VERSION ""

NS_ :

BS_:

BU_: Tester GW LAS

BO_ 1891 DIAG_Phy_Req_CAN: 8 Tester
 SG_ Phys_Diag_Rx_CAN : 7|8@0+ (1,0) [0|0] ""  LAS

BO_ 1899 DIAG_Response_CAN: 8 LAS
 SG_ Diag_Response_CAN : 7|8@0+ (1,0) [0|0] "" Vector__XXX

BO_ 2015 DIAG_Function_Req: 8 Tester
 SG_ Functional_Diag_Rx : 7|8@0+ (1,0) [0|0] ""  LAS

BO_ 1874 DIAG_Phy_Req: 64 Tester
 SG_ Phys_Diag_Rx : 7|64@0+ (1,0) [0|0] ""  LAS

BO_ 1882 DIAG_Response: 64 LAS
 SG_ Diag_Response : 7|64@0+ (1,0) [0|0] "" Vector__XXX

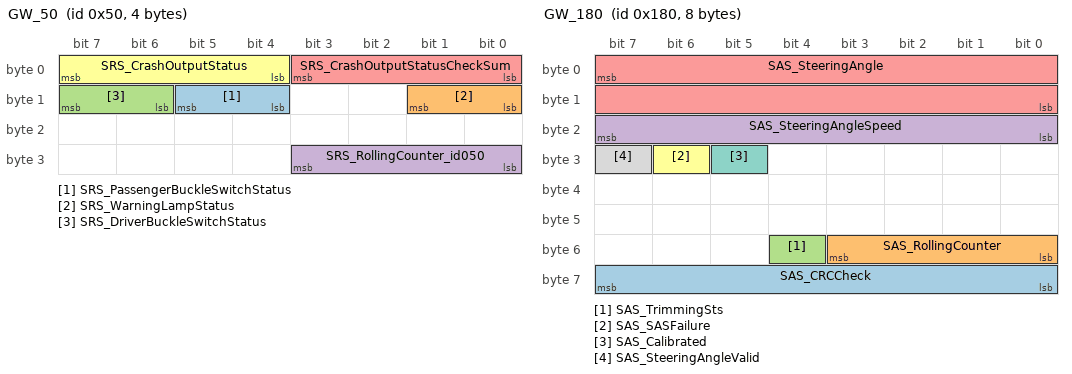
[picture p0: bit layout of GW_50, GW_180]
BO_ 80 GW_50: 4 GW
 SG_ SRS_PassengerBuckleSwitchStatus : 13|2@0+ (1,0) [0|3] ""  LAS
 SG_ SRS_WarningLampStatus : 9|2@0+ (1,0) [0|3] ""  LAS
 SG_ SRS_DriverBuckleSwitchStatus : 15|2@0+ (1,0) [0|3] ""  LAS
 SG_ SRS_RollingCounter_id050 : 27|4@0+ (1,0) [0|15] ""  LAS
 SG_ SRS_CrashOutputStatusCheckSum : 3|4@0+ (1,0) [0|15] ""  LAS
 SG_ SRS_CrashOutputStatus : 7|4@0+ (1,0) [0|15] ""  LAS

BO_ 384 GW_180: 8 GW
 SG_ SAS_CRCCheck : 63|8@0+ (1,0) [0|255] ""  LAS
 SG_ SAS_RollingCounter : 51|4@0+ (1,0) [0|15] ""  LAS
 SG_ SAS_TrimmingSts : 52|1@0+ (1,0) [0|1] ""  LAS
 SG_ SAS_SteeringAngleSpeed : 23|8@0+ (4,0) [0|1016] "deg/s"  LAS
 SG_ SAS_SteeringAngle : 7|16@0- (0.1,0) [-780|3276.7] "degree"  LAS
 SG_ SAS_SASFailure : 30|1@0+ (1,0) [0|1] ""  LAS
 SG_ SAS_Calibrated : 29|1@0+ (1,0) [0|1] ""  LAS
 SG_ SAS_SteeringAngleValid : 31|1@0+ (1,0) [0|1] ""  LAS

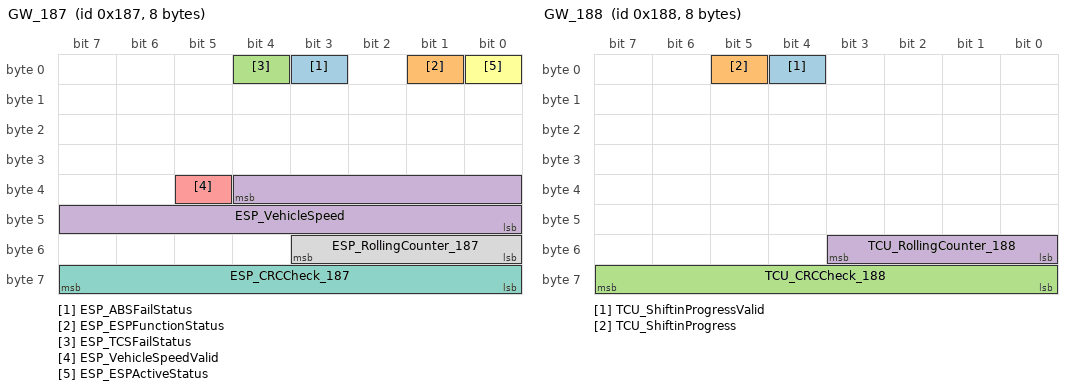
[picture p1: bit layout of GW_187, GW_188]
BO_ 391 GW_187: 8 GW
 SG_ ESP_ABSFailStatus : 3|1@0+ (1,0) [0|1] ""  LAS
 SG_ ESP_ESPFunctionStatus : 1|1@0+ (1,0) [0|1] ""  LAS
 SG_ ESP_TCSFailStatus : 4|1@0+ (1,0) [0|1] ""  LAS
 SG_ ESP_VehicleSpeed : 36|13@0+ (0.05625,0) [0|360] "km/h"  LAS
 SG_ ESP_VehicleSpeedValid : 37|1@0+ (1,0) [0|1] ""  LAS
 SG_ ESP_ESPActiveStatus : 0|1@0+ (1,0) [0|1] ""  LAS
 SG_ ESP_CRCCheck_187 : 63|8@0+ (1,0) [0|255] ""  LAS
 SG_ ESP_RollingCounter_187 : 51|4@0+ (1,0) [0|15] ""  LAS

BO_ 392 GW_188: 8 GW
 SG_ TCU_ShiftinProgressValid : 4|1@0+ (1,0) [0|1] ""  LAS
 SG_ TCU_ShiftinProgress : 5|1@0+ (1,0) [0|1] ""  LAS
 SG_ TCU_CRCCheck_188 : 63|8@0+ (1,0) [0|255] ""  LAS
 SG_ TCU_RollingCounter_188 : 51|4@0+ (1,0) [0|15] ""  LAS

BO_ 406 GW_196: 8 GW
 SG_ EMS_AccPedal : 47|8@0+ (0.392,0) [0|99.568] "%"  LAS
 SG_ EMS_EngineSpeed : 23|16@0+ (0.25,0) [0|16383.5] "Rpm"  LAS

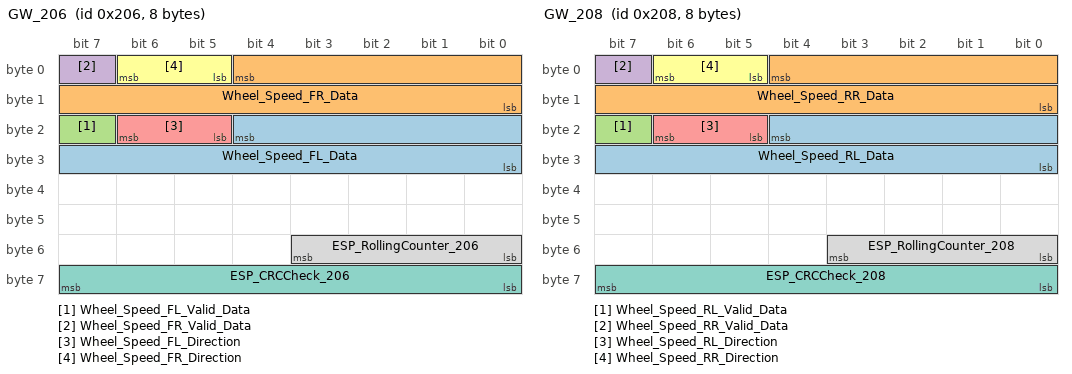
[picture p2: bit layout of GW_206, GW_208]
BO_ 518 GW_206: 8 GW
 SG_ Wheel_Speed_FL_Data : 20|13@0+ (0.05625,0) [0|360] "km/h"  LAS
 SG_ Wheel_Speed_FR_Data : 4|13@0+ (0.05625,0) [0|360] "km/h"  LAS
 SG_ Wheel_Speed_FL_Valid_Data : 23|1@0+ (1,0) [0|1] ""  LAS
 SG_ Wheel_Speed_FR_Valid_Data : 7|1@0+ (1,0) [0|1] ""  LAS
 SG_ Wheel_Speed_FL_Direction : 22|2@0+ (1,0) [0|3] ""  LAS
 SG_ Wheel_Speed_FR_Direction : 6|2@0+ (1,0) [0|3] ""  LAS
 SG_ ESP_CRCCheck_206 : 63|8@0+ (1,0) [0|255] ""  LAS
 SG_ ESP_RollingCounter_206 : 51|4@0+ (1,0) [0|15] ""  LAS

BO_ 520 GW_208: 8 GW
 SG_ Wheel_Speed_RL_Data : 20|13@0+ (0.05625,0) [0|360] "km/h"  LAS
 SG_ Wheel_Speed_RR_Data : 4|13@0+ (0.05625,0) [0|360] "km/h"  LAS
 SG_ Wheel_Speed_RL_Valid_Data : 23|1@0+ (1,0) [0|1] ""  LAS
 SG_ Wheel_Speed_RR_Valid_Data : 7|1@0+ (1,0) [0|1] ""  LAS
 SG_ Wheel_Speed_RL_Direction : 22|2@0+ (1,0) [0|3] ""  LAS
 SG_ Wheel_Speed_RR_Direction : 6|2@0+ (1,0) [0|3] ""  LAS
 SG_ ESP_CRCCheck_208 : 63|8@0+ (1,0) [0|255] ""  LAS
 SG_ ESP_RollingCounter_208 : 51|4@0+ (1,0) [0|15] ""  LAS

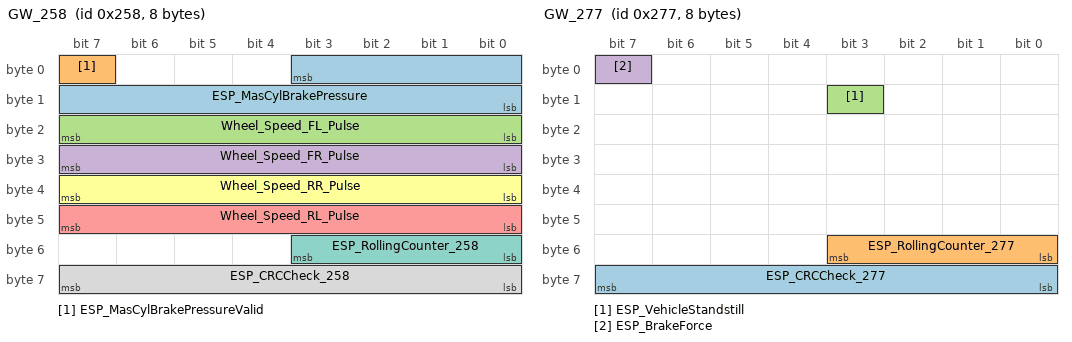
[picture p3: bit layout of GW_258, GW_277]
BO_ 600 GW_258: 8 GW
 SG_ ESP_MasCylBrakePressure : 3|12@0+ (0.1,0) [0|250] "Bar"  LAS
 SG_ ESP_MasCylBrakePressureValid : 7|1@0+ (1,0) [0|1] ""  LAS
 SG_ Wheel_Speed_FL_Pulse : 23|8@0+ (1,0) [0|254] ""  LAS
 SG_ Wheel_Speed_FR_Pulse : 31|8@0+ (1,0) [0|254] ""  LAS
 SG_ Wheel_Speed_RL_Pulse : 47|8@0+ (1,0) [0|254] ""  LAS
 SG_ Wheel_Speed_RR_Pulse : 39|8@0+ (1,0) [0|254] ""  LAS
 SG_ ESP_RollingCounter_258 : 51|4@0+ (1,0) [0|15] ""  LAS
 SG_ ESP_CRCCheck_258 : 63|8@0+ (1,0) [0|255] ""  LAS

BO_ 631 GW_277: 8 GW
 SG_ ESP_CRCCheck_277 : 63|8@0+ (1,0) [0|255] ""  LAS
 SG_ ESP_RollingCounter_277 : 51|4@0+ (1,0) [0|15] ""  LAS
 SG_ ESP_VehicleStandstill : 11|1@0+ (1,0) [0|1] ""  LAS
 SG_ ESP_BrakeForce : 7|1@0+ (1,0) [0|1] ""  LAS

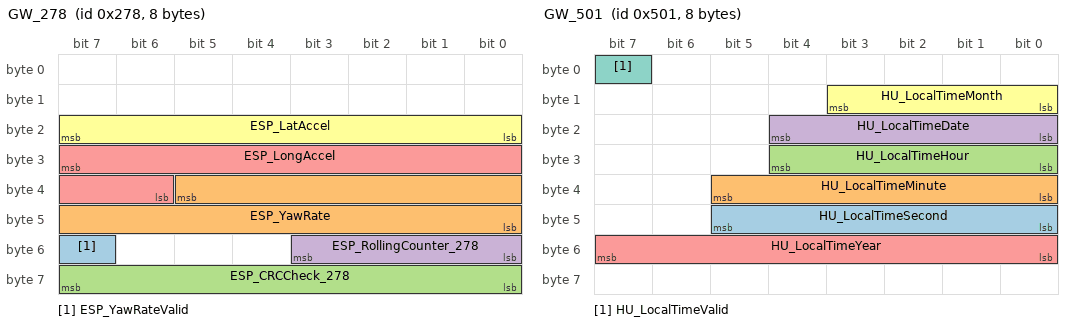
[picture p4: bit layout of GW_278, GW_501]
BO_ 632 GW_278: 8 GW
 SG_ ESP_YawRateValid : 55|1@0+ (1,0) [0|1] ""  LAS
 SG_ ESP_YawRate : 37|14@0+ (0.01,-81.91) [-81.91|81.91] "degree/s"  LAS
 SG_ ESP_CRCCheck_278 : 63|8@0+ (1,0) [0|255] ""  LAS
 SG_ ESP_RollingCounter_278 : 51|4@0+ (1,0) [0|15] ""  LAS
 SG_ ESP_LongAccel : 31|10@0+ (0.03125,-16) [-16|15.90625] "m/s2"  LAS
 SG_ ESP_LatAccel : 23|8@0+ (0.1,-12.7) [-12.7|12.7] "m/s2"  LAS

BO_ 832 GW_340: 8 GW
 SG_ AC_FrBlowType : 2|3@0+ (1,0) [0|7] ""  LAS

BO_ 870 GW_366: 8 GW
 SG_ AC_EnvironmentalTemp : 23|8@0+ (0.5,-40) [-40|87.5] "degreeC"  LAS
 SG_ AC_EnvironmentalTempVD : 8|1@0+ (1,0) [0|1] ""  LAS

BO_ 903 GW_387: 8 GW
 SG_ BCM_RainfallLevel : 19|4@0+ (1,0) [0|15] ""  LAS
 SG_ BCM_FrontWiperStatus : 25|2@0+ (1,0) [0|3] ""  LAS

BO_ 912 GW_390: 8 GW
 SG_ BCM_SOH_LifePercent : 15|8@0+ (1,0) [0|100] "%"  LAS
 SG_ BCM_PMSLevel : 5|3@0+ (1,0) [0|7] ""  LAS

BO_ 1280 GW_500: 8 GW
 SG_ HU_CurrentLocationLatitude : 35|28@0+ (1E-006,-134.217727) [-134.217727|90] "degree"  LAS
 SG_ HU_CurrentLocationLongitude : 4|29@0+ (1E-006,-268.435455) [-268.435455|180] "degree"  LAS

BO_ 1281 GW_501: 8 GW
 SG_ HU_LocalTimeSecond : 45|6@0+ (1,0) [0|59] "second"  LAS
 SG_ HU_LocalTimeMinute : 37|6@0+ (1,0) [0|59] "minute"  LAS
 SG_ HU_LocalTimeHour : 28|5@0+ (1,0) [0|23] "hour"  LAS
 SG_ HU_LocalTimeDate : 20|5@0+ (1,0) [1|31] "day"  LAS
 SG_ HU_LocalTimeYear : 55|8@0+ (1,2013) [2013|2268] "year"  LAS
 SG_ HU_LocalTimeMonth : 11|4@0+ (1,0) [1|12] "month"  LAS
 SG_ HU_LocalTimeValid : 7|1@0+ (1,0) [0|1] ""  LAS

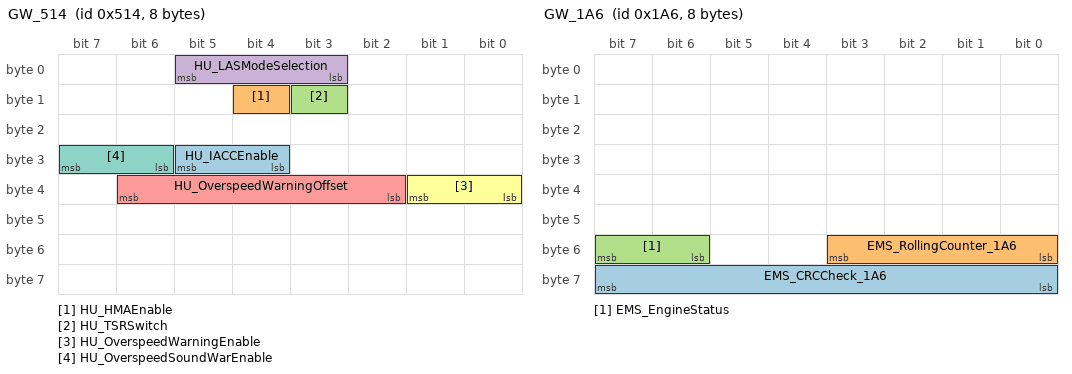
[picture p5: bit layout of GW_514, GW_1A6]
BO_ 1300 GW_514: 8 GW
 SG_ HU_IACCEnable : 29|2@0+ (1,0) [0|3] ""  LAS
 SG_ HU_HMAEnable : 12|1@0+ (1,0) [0|1] ""  LAS
 SG_ HU_TSRSwitch : 11|1@0+ (1,0) [0|1] ""  LAS
 SG_ HU_LASModeSelection : 5|3@0+ (1,0) [0|7] ""  LAS
 SG_ HU_OverspeedWarningOffset : 38|5@0+ (1,-10) [-10|10] ""  LAS
 SG_ HU_OverspeedWarningEnable : 33|2@0+ (1,0) [0|3] ""  LAS
 SG_ HU_OverspeedSoundWarEnable : 31|2@0+ (1,0) [0|3] ""  LAS

BO_ 1328 GW_530: 8 GW
 SG_ IP_TotalOdometer : 23|24@0+ (0.1,0) [0|999999] "Km"  LAS

BO_ 422 GW_1A6: 8 GW
 SG_ EMS_CRCCheck_1A6 : 63|8@0+ (1,0) [0|255] ""  LAS
 SG_ EMS_RollingCounter_1A6 : 51|4@0+ (1,0) [0|15] ""  LAS
 SG_ EMS_EngineStatus : 55|2@0+ (1,0) [0|3] ""  LAS

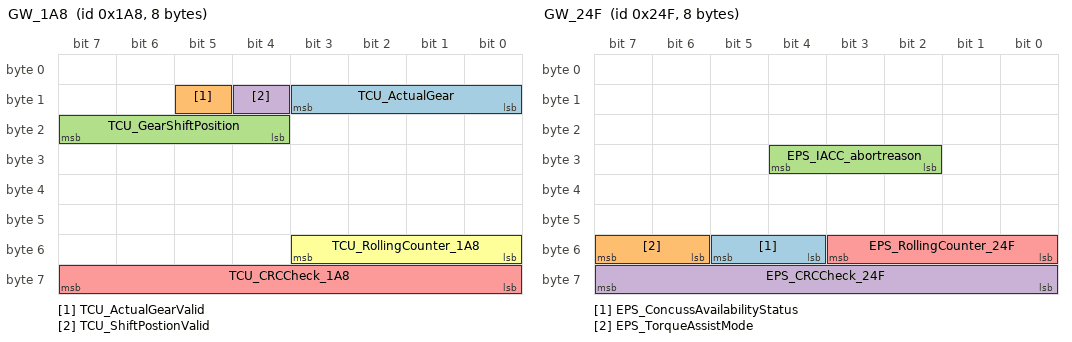
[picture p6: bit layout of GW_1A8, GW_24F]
BO_ 424 GW_1A8: 8 GW
 SG_ TCU_ActualGear : 11|4@0+ (1,0) [0|15] ""  LAS
 SG_ TCU_ActualGearValid : 13|1@0+ (1,0) [0|1] ""  LAS
 SG_ TCU_GearShiftPosition : 23|4@0+ (1,0) [0|15] ""  LAS
 SG_ TCU_ShiftPostionValid : 12|1@0+ (1,0) [0|1] ""  LAS
 SG_ TCU_CRCCheck_1A8 : 63|8@0+ (1,0) [0|255] ""  LAS
 SG_ TCU_RollingCounter_1A8 : 51|4@0+ (1,0) [0|15] ""  LAS

BO_ 591 GW_24F: 8 GW
 SG_ EPS_ConcussAvailabilityStatus : 53|2@0+ (1,0) [0|3] ""  LAS
 SG_ EPS_TorqueAssistMode : 55|2@0+ (1,0) [0|3] ""  LAS
 SG_ EPS_IACC_abortreason : 28|3@0+ (1,0) [0|7] ""  LAS
 SG_ EPS_CRCCheck_24F : 63|8@0+ (1,0) [0|255] ""  LAS
 SG_ EPS_RollingCounter_24F : 51|4@0+ (1,0) [0|15] ""  LAS

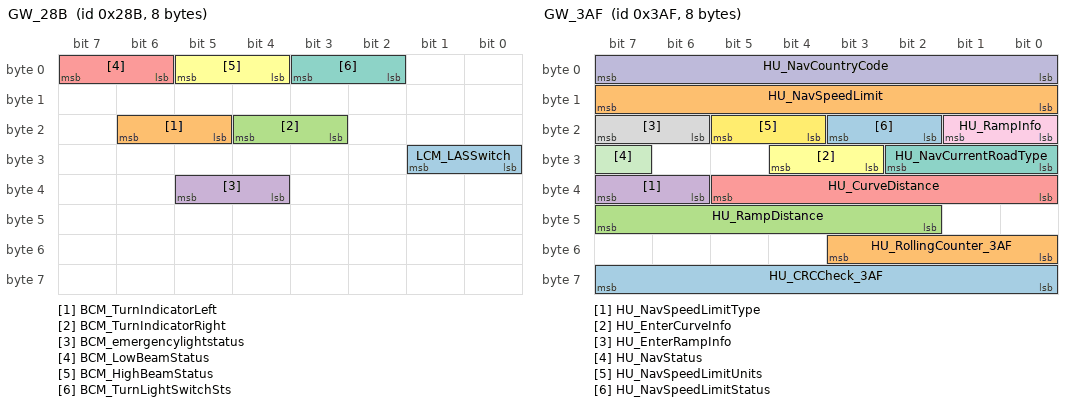
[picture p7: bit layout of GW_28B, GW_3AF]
BO_ 651 GW_28B: 8 GW
 SG_ LCM_LASSwitch : 25|2@0+ (1,0) [0|3] ""  LAS
 SG_ BCM_TurnIndicatorLeft : 22|2@0+ (1,0) [0|3] ""  LAS
 SG_ BCM_TurnIndicatorRight : 20|2@0+ (1,0) [0|3] ""  LAS
 SG_ BCM_emergencylightstatus : 37|2@0+ (1,0) [0|3] ""  LAS
 SG_ BCM_LowBeamStatus : 7|2@0+ (1,0) [0|3] ""  LAS
 SG_ BCM_HighBeamStatus : 5|2@0+ (1,0) [0|3] ""  LAS
 SG_ BCM_TurnLightSwitchSts : 3|2@0+ (1,0) [0|3] ""  LAS

BO_ 943 GW_3AF: 8 GW
 SG_ HU_CRCCheck_3AF : 63|8@0+ (1,0) [0|255] ""  LAS
 SG_ HU_RollingCounter_3AF : 51|4@0+ (1,0) [0|15] ""  LAS
 SG_ HU_RampDistance : 47|6@0+ (10,0) [0|630] "m"  LAS
 SG_ HU_NavSpeedLimitType : 39|2@0+ (1,0) [0|3] ""  LAS
 SG_ HU_CurveDistance : 37|6@0+ (10,0) [0|630] "m"  LAS
 SG_ HU_EnterCurveInfo : 28|2@0+ (1,0) [0|3] ""  LAS
 SG_ HU_NavCurrentRoadType : 26|3@0+ (1,0) [0|7] ""  LAS
 SG_ HU_EnterRampInfo : 23|2@0+ (1,0) [0|3] ""  LAS
 SG_ HU_RampInfo : 17|2@0+ (1,0) [0|3] ""  LAS
 SG_ HU_NavCountryCode : 7|8@0+ (1,0) [0|255] ""  LAS
 SG_ HU_NavStatus : 31|1@0+ (1,0) [0|1] ""  LAS
 SG_ HU_NavSpeedLimitUnits : 21|2@0+ (1,0) [0|3] ""  LAS
 SG_ HU_NavSpeedLimitStatus : 19|2@0+ (1,0) [0|3] ""  LAS
 SG_ HU_NavSpeedLimit : 15|8@0+ (1,0) [0|255] ""  LAS

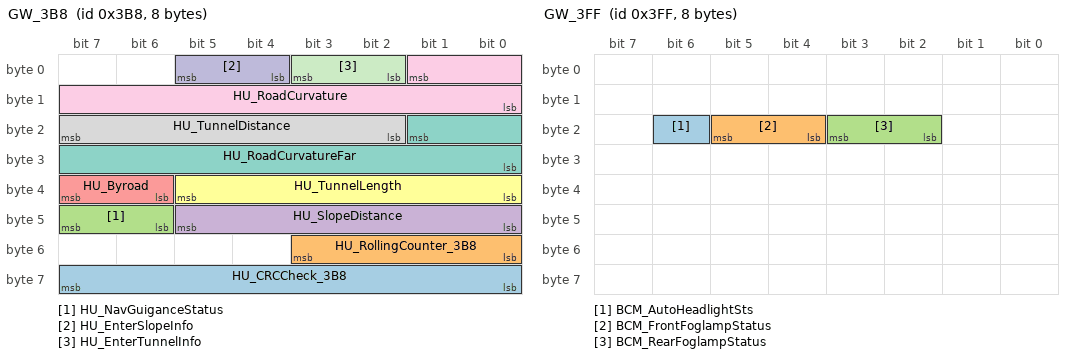
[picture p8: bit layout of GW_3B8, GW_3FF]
BO_ 952 GW_3B8: 8 GW
 SG_ HU_CRCCheck_3B8 : 63|8@0+ (1,0) [0|255] ""  LAS
 SG_ HU_RollingCounter_3B8 : 51|4@0+ (1,0) [0|15] ""  LAS
 SG_ HU_NavGuiganceStatus : 47|2@0+ (1,0) [0|3] ""  LAS
 SG_ HU_SlopeDistance : 45|6@0+ (10,0) [0|630] "m"  LAS
 SG_ HU_Byroad : 39|2@0+ (1,0) [0|3] ""  LAS
 SG_ HU_TunnelLength : 37|6@0+ (1,0) [0|63] "m"  LAS
 SG_ HU_RoadCurvatureFar : 17|10@0+ (1,0) [0|1023] ""  LAS
 SG_ HU_TunnelDistance : 23|6@0+ (10,0) [0|630] "m"  LAS
 SG_ HU_RoadCurvature : 1|10@0+ (1,0) [0|1023] ""  LAS
 SG_ HU_EnterSlopeInfo : 5|2@0+ (1,0) [0|3] ""  LAS
 SG_ HU_EnterTunnelInfo : 3|2@0+ (1,0) [0|3] ""  LAS

BO_ 1023 GW_3FF: 8 GW
 SG_ BCM_AutoHeadlightSts : 22|1@0+ (1,0) [0|1] ""  LAS
 SG_ BCM_FrontFoglampStatus : 21|2@0+ (1,0) [0|3] ""  LAS
 SG_ BCM_RearFoglampStatus : 19|2@0+ (1,0) [0|3] ""  LAS

BO_ 583 APA_247: 32 GW
 SG_ APA_APAOnOff : 6|1@0+ (1,0) [0|1] ""  LAS

BO_ 746 ADS_2EA: 16 GW
 SG_ ADS_LCDAR_BSD_LCAStatus : 23|2@0+ (1,0) [0|3] ""  LAS
 SG_ ADS_LCDAR_Left_BSD_LCAStatus : 3|2@0+ (1,0) [0|3] ""  LAS

BO_ 922 LAS_39A: 32 LAS
 SG_ LAS_TSRRightLaneStatus : 55|3@0+ (1,0) [0|7] "" Vector__XXX
 SG_ LAS_TSRLeftLaneStatus : 47|3@0+ (1,0) [0|7] "" Vector__XXX
 SG_ LAS_CRCCheck_3C0 : 191|8@0+ (1,0) [0|255] "" Vector__XXX
 SG_ LAS_RollingCounter_3C0 : 179|4@0+ (1,0) [0|15] "" Vector__XXX
 SG_ LAS_TSRRightLaneSpdLimit : 143|8@0+ (1,0) [0|255] "" Vector__XXX
 SG_ LAS_TSRLeftLaneSpdLimit : 135|8@0+ (1,0) [0|255] "" Vector__XXX
 SG_ LAS_CRCCheck_3D4 : 127|8@0+ (1,0) [0|255] "" Vector__XXX
 SG_ LAS_RollingCounter_3D4 : 115|4@0+ (1,0) [0|15] "" Vector__XXX
 SG_ LAS_TLAStopLine_HostLane : 111|8@0+ (1,0) [0|255] "" Vector__XXX
 SG_ LAS_TLADistance_HostLane : 103|8@0+ (1,0) [0|255] "" Vector__XXX
 SG_ LAS_TLACountDownTime_HostLane : 94|7@0+ (1,0) [0|127] "" Vector__XXX
 SG_ LAS_TSRMandatorySign : 70|4@0+ (1,0) [0|15] "" Vector__XXX
 SG_ LAS_TSRWarningSign : 83|4@0+ (1,0) [0|15] "" Vector__XXX
 SG_ LAS_TSRProhibitionSign : 66|5@0+ (1,0) [0|31] "" Vector__XXX
 SG_ LAS_CRCCheck_332 : 63|8@0+ (1,0) [0|255] "" Vector__XXX
 SG_ LAS_RollingCounter_332 : 51|4@0+ (1,0) [0|15] "" Vector__XXX
 SG_ LAS_OverspeedSoundWarningEnSt : 27|1@0+ (1,0) [0|1] "" Vector__XXX
 SG_ LAS_TSREnable : 30|1@0+ (1,0) [0|1] "" Vector__XXX
 SG_ LAS_HMAEnableStatus : 22|1@0+ (1,0) [0|1] "" Vector__XXX
 SG_ LAS_HMALightDistribution : 8|1@0+ (1,0) [0|1] "" Vector__XXX
 SG_ LAS_HMAStatus : 44|2@0+ (1,0) [0|3] "" Vector__XXX
 SG_ LAS_TSRHostSpdLimitUnits : 41|2@0+ (1,0) [0|3] "" Vector__XXX
 SG_ LAS_TSRHostSpdLimit : 39|8@0+ (1,0) [0|255] "" Vector__XXX
 SG_ LAS_TSRStatus : 26|3@0+ (1,0) [0|7] "" Vector__XXX
 SG_ LAS_FrontCameraCalibrationStatus : 20|2@0+ (1,0) [0|3] "" Vector__XXX
 SG_ LAS_FrontCameraFailureStatus : 17|2@0+ (1,0) [0|3] "" Vector__XXX
 SG_ LAS_OverspeedWarningOffset : 14|5@0+ (1,-10) [-10|10] "km/h" Vector__XXX
 SG_ LAS_OverspeedWarningEnableStatus : 15|1@0+ (1,0) [0|1] "" Vector__XXX
 SG_ LAS_OverspeedSoundWarning : 2|1@0+ (1,0) [0|1] "" Vector__XXX
 SG_ LAS_OverspeedVisualWarning : 5|1@0+ (1,0) [0|1] "" Vector__XXX
 SG_ LAS_CRCCheck_37D : 255|8@0+ (1,0) [0|255] "" Vector__XXX
 SG_ LAS_RollingCounter_37D : 243|4@0+ (1,0) [0|15] "" Vector__XXX
 SG_ LAS_TLAArrowDirection_RightLane : 236|3@0+ (1,0) [0|7] "" Vector__XXX
 SG_ LAS_TLAObjectType_RightLane : 239|3@0+ (1,0) [0|7] "" Vector__XXX
 SG_ LAS_TLAObjectStatus_RightLane : 247|2@0+ (1,0) [0|3] "" Vector__XXX
 SG_ LAS_TLAObjectColour_RightLane : 225|2@0+ (1,0) [0|3] "" Vector__XXX
 SG_ LAS_TLAObjectDetection_RightLane : 227|1@0+ (1,0) [0|1] "" Vector__XXX
 SG_ LAS_TLAArrowDirection_LeftLane : 216|3@0+ (1,0) [0|7] "" Vector__XXX
 SG_ LAS_TLAObjectType_LeftLane : 219|3@0+ (1,0) [0|7] "" Vector__XXX
 SG_ LAS_TLAObjectStatus_LeftLane : 245|2@0+ (1,0) [0|3] "" Vector__XXX
 SG_ LAS_TLAObjectColour_LeftLane : 221|2@0+ (1,0) [0|3] "" Vector__XXX
 SG_ LAS_TLAObjectDetection_LeftLane : 223|1@0+ (1,0) [0|1] "" Vector__XXX
 SG_ LAS_TLAArrowDirection_HostLane : 215|3@0+ (1,0) [0|7] "" Vector__XXX
 SG_ LAS_TLAObjectStatus_HostLane : 199|2@0+ (1,0) [0|3] "" Vector__XXX
 SG_ LAS_TLAObjectType_HostLane : 212|3@0+ (1,0) [0|7] "" Vector__XXX
 SG_ LAS_TLAObjectColour_HostLane : 204|2@0+ (1,0) [0|3] "" Vector__XXX
 SG_ LAS_TLAObjectDetection_HostLane : 200|1@0+ (1,0) [0|1] "" Vector__XXX
 SG_ LAS_TLAWarninglevel : 197|2@0+ (1,0) [0|3] "" Vector__XXX
 SG_ LAS_TLAStatus : 193|2@0+ (1,0) [0|3] "" Vector__XXX
 SG_ LAS_TLAEnable : 194|1@0+ (1,0) [0|1] "" Vector__XXX

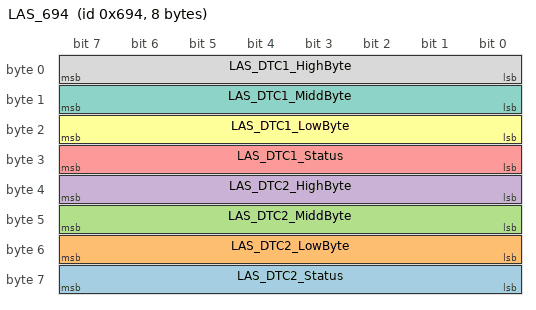
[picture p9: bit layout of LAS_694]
BO_ 1684 LAS_694: 8 LAS
 SG_ LAS_DTC2_Status : 63|8@0+ (1,0) [0|255] "" Vector__XXX
 SG_ LAS_DTC2_LowByte : 55|8@0+ (1,0) [0|255] "" Vector__XXX
 SG_ LAS_DTC2_MiddByte : 47|8@0+ (1,0) [0|255] "" Vector__XXX
 SG_ LAS_DTC2_HighByte : 39|8@0+ (1,0) [0|255] "" Vector__XXX
 SG_ LAS_DTC1_Status : 31|8@0+ (1,0) [0|255] "" Vector__XXX
 SG_ LAS_DTC1_LowByte : 23|8@0+ (1,0) [0|255] "" Vector__XXX
 SG_ LAS_DTC1_MiddByte : 15|8@0+ (1,0) [0|255] "" Vector__XXX
 SG_ LAS_DTC1_HighByte : 7|8@0+ (1,0) [0|255] "" Vector__XXX

BO_ 999 GW_3E7: 8 GW
 SG_ BCM_Status_Temp : 51|2@0+ (1,0) [0|3] ""  LAS
 SG_ BCM_T_BATT : 39|8@0+ (1,-40) [-40|215] ""  LAS

BO_ 1000 GW_3E8: 8 GW
 SG_ BCM_SOF_Q_STATE : 51|2@0+ (1,0) [0|3] ""  LAS
 SG_ BCM_SOF_Q : 15|8@0+ (0.5,0) [0|127.5] "Ah"  LAS

BO_TX_BU_ 1882 : Tester,LAS;

CM_ BO_ 2015 " ";
CM_ BO_ 1874 " ";
CM_ BO_ 1882 " ";
CM_ BO_ 80 "
20ms 10 ";
CM_ SG_ 80 SRS_PassengerBuckleSwitchStatus "For PDM is configured projects:
(if PDM is configured, logical detection with PDM is required)
0x0: [Buckled] or [Unbuckled and passenger not occupied]
0x1: [Unbuckle and passenger occupied]
0x2: Not Used
0x3: Not Used
 ";
CM_ BO_ 384 "PCAN_SAS»
EPS EPSCAN_EPS ";
CM_ BO_ 391 " ";
CM_ SG_ 391 ESP_VehicleSpeed "TCUDCT ";
CM_ SG_ 391 ESP_VehicleSpeedValid "TCUDCT ";
CM_ SG_ 391 ESP_ESPActiveStatus "TCUDCT ";
CM_ SG_ 391 ESP_CRCCheck_187 "AT/DCT ";
CM_ SG_ 391 ESP_RollingCounter_187 "AT/DCT ";
CM_ BO_ 392 " ";
CM_ SG_ 392 TCU_ShiftinProgressValid "AT/DCT ";
CM_ SG_ 392 TCU_ShiftinProgress "AT/DCT ";
CM_ SG_ 392 TCU_CRCCheck_188 " ";
CM_ SG_ 392 TCU_RollingCounter_188 "AT/DCT
rollingcounter ";
CM_ BO_ 406 " ";
CM_ BO_ 518 " ";
CM_ SG_ 518 ESP_CRCCheck_206 " ";
CM_ SG_ 518 ESP_RollingCounter_206 "rollingcounter ";
CM_ BO_ 520 " ";
CM_ SG_ 520 ESP_CRCCheck_208 " ";
CM_ SG_ 520 ESP_RollingCounter_208 "rollingcounter ";
CM_ BO_ 600 " ";
CM_ SG_ 600 ESP_MasCylBrakePressure "indicatedthepressureofbrakemastercylinder,butnotthepressureofbrake ";
CM_ SG_ 600 Wheel_Speed_FL_Pulse "All4wheelpulsesignalsaresentbyABSwithoutfiltering.Theriseedgeandfalledgearebothcountedinit,thewheelpulsemustbesequentialintheway0,1,2,254,0,4";
CM_ SG_ 600 Wheel_Speed_FR_Pulse "All4wheelpulsesignalsaresentbyABSwithoutfiltering.Theriseedgeandfalledgearebothcountedinit,thewheelpulsemustbesequentialintheway0,1,2,254,0,3 ";
CM_ SG_ 600 Wheel_Speed_RL_Pulse "All4wheelpulsesignalsaresentbyABSwithoutfiltering.Theriseedgeandfalledgearebothcountedinit,thewheelpulsemustbesequentialintheway0,1,2,254,0,2 ";
CM_ SG_ 600 Wheel_Speed_RR_Pulse "All4wheelpulsesignalsaresentbyABSwithoutfiltering.Theriseedgeandfalledgearebothcountedinit,thewheelpulsemustbesequentialintheway0,1,2,254,0,1 ";
CM_ SG_ 600 ESP_CRCCheck_258 " ";
CM_ BO_ 631 " ";
CM_ SG_ 631 ESP_CRCCheck_277 " ";
CM_ SG_ 631 ESP_RollingCounter_277 "rollingcounter ";
CM_ BO_ 632 " ";
CM_ SG_ 632 ESP_YawRate " ";
CM_ SG_ 632 ESP_CRCCheck_278 " ";
CM_ SG_ 632 ESP_RollingCounter_278 "rollingcounter ";
CM_ SG_ 632 ESP_LongAccel " ";
CM_ SG_ 632 ESP_LatAccel " ";
CM_ BO_ 832 " ";
CM_ BO_ 870 " ";
CM_ BO_ 903 " ";
CM_ BO_ 912 " ";
CM_ SG_ 912 BCM_PMSLevel "DBC ";
CM_ BO_ 1280 " ";
CM_ BO_ 1281 " ";
CM_ BO_ 1300 " ";
CM_ SG_ 1300 HU_IACCEnable "513()514()514() ";
CM_ SG_ 1300 HU_HMAEnable "513()514()514() ";
CM_ SG_ 1300 HU_TSRSwitch "513()514()514() ";
CM_ SG_ 1300 HU_LASModeSelection "513()514()514() ";
CM_ SG_ 1300 HU_OverspeedWarningOffset "513()514()514() ";
CM_ SG_ 1300 HU_OverspeedWarningEnable "513()514()514() ";
CM_ SG_ 1300 HU_OverspeedSoundWarEnable "513()514()514() ";
CM_ BO_ 1328 " ";
CM_ SG_ 1328 IP_TotalOdometer "GW ";
CM_ BO_ 422 " ";
CM_ SG_ 422 EMS_CRCCheck_1A6 " ";
CM_ BO_ 424 " ";
CM_ SG_ 424 TCU_ActualGear "AT/DCT ";
CM_ SG_ 424 TCU_ActualGearValid "AT/DCT ";
CM_ SG_ 424 TCU_GearShiftPosition "AT/DCT ";
CM_ SG_ 424 TCU_ShiftPostionValid "AT/DCT ";
CM_ SG_ 424 TCU_CRCCheck_1A8 " ";
CM_ SG_ 424 TCU_RollingCounter_1A8 "AT/DCT
rollingcounter ";
CM_ BO_ 591 "L2EPSCAN L2PCAN ";
CM_ BO_ 651 " ";
CM_ BO_ 943 " ";
CM_ BO_ 952 " ";
CM_ BO_ 1023 " ";
CM_ BO_ 583 " ";
CM_ BO_ 746 " ";
CM_ SG_ 746 ADS_LCDAR_Left_BSD_LCAStatus " ";
CM_ BO_ 922 " ";
CM_ SG_ 922 LAS_TSRRightLaneStatus "GW ";
CM_ SG_ 922 LAS_TSRLeftLaneStatus "GW ";
CM_ SG_ 922 LAS_CRCCheck_3C0 "
 ";
CM_ SG_ 922 LAS_RollingCounter_3C0 "rolling counter ";
CM_ SG_ 922 LAS_TSRRightLaneSpdLimit "GW
0x0=no speed limit detected;
0x1=SL5;
0x2=SL10;
0x32=SL160;
0x33~0x253= Reserved;
0x254=Unknown;
0x255=SLEND ";
CM_ SG_ 922 LAS_TSRLeftLaneSpdLimit "GW
0x0=no speed limit detected;
0x1=SL5;
0x2=SL10;
0x32=SL160;
0x33~0x253= Reserved;
0x254=Unknown;
0x255=SLEND ";
CM_ SG_ 922 LAS_CRCCheck_3D4 "
 ";
CM_ SG_ 922 LAS_RollingCounter_3D4 "rolling counter ";
CM_ SG_ 922 LAS_TLAStopLine_HostLane " ";
CM_ SG_ 922 LAS_TLADistance_HostLane " ";
CM_ SG_ 922 LAS_TLACountDownTime_HostLane " ";
CM_ SG_ 922 LAS_TSRMandatorySign " ";
CM_ SG_ 922 LAS_TSRWarningSign " ";
CM_ SG_ 922 LAS_TSRProhibitionSign " ";
CM_ SG_ 922 LAS_CRCCheck_332 "
 ";
CM_ SG_ 922 LAS_RollingCounter_332 "rolling counter ";
CM_ SG_ 922 LAS_HMALightDistribution "GW ";
CM_ SG_ 922 LAS_HMAStatus "GW ";
CM_ SG_ 922 LAS_TSRHostSpdLimitUnits "GW ";
CM_ SG_ 922 LAS_TSRStatus "GW ";
CM_ SG_ 922 LAS_FrontCameraCalibrationStatus "LASLAS APAAVM ";
CM_ SG_ 922 LAS_FrontCameraFailureStatus "LASLAS APAAVM ";
CM_ SG_ 922 LAS_CRCCheck_37D " ";
CM_ SG_ 922 LAS_RollingCounter_37D "rolling counter ";
CM_ SG_ 922 LAS_TLAArrowDirection_RightLane " ";
CM_ SG_ 922 LAS_TLAObjectType_RightLane " ";
CM_ SG_ 922 LAS_TLAObjectStatus_RightLane " ";
CM_ SG_ 922 LAS_TLAObjectColour_RightLane " ";
CM_ SG_ 922 LAS_TLAObjectDetection_RightLane " ";
CM_ SG_ 922 LAS_TLAArrowDirection_LeftLane " ";
CM_ SG_ 922 LAS_TLAObjectType_LeftLane " ";
CM_ SG_ 922 LAS_TLAObjectStatus_LeftLane " ";
CM_ SG_ 922 LAS_TLAObjectColour_LeftLane " ";
CM_ SG_ 922 LAS_TLAObjectDetection_LeftLane " ";
CM_ SG_ 922 LAS_TLAArrowDirection_HostLane " ";
CM_ SG_ 922 LAS_TLAObjectStatus_HostLane " ";
CM_ SG_ 922 LAS_TLAObjectType_HostLane " ";
CM_ SG_ 922 LAS_TLAObjectColour_HostLane " ";
CM_ SG_ 922 LAS_TLAObjectDetection_HostLane " ";
CM_ SG_ 922 LAS_TLAWarninglevel " ";
CM_ SG_ 922 LAS_TLAStatus " ";
CM_ SG_ 922 LAS_TLAEnable " ";
CM_ BO_ 1684 " ";
CM_ SG_ 1684 LAS_DTC2_Status "DTC ";
CM_ SG_ 1684 LAS_DTC2_LowByte "DTC ";
CM_ SG_ 1684 LAS_DTC2_MiddByte "DTC ";
CM_ SG_ 1684 LAS_DTC2_HighByte "DTC ";
CM_ SG_ 1684 LAS_DTC1_Status "DTC ";
CM_ SG_ 1684 LAS_DTC1_LowByte "DTC ";
CM_ SG_ 1684 LAS_DTC1_MiddByte "DTC ";
CM_ SG_ 1684 LAS_DTC1_HighByte "DTC ";
CM_ BO_ 999 " ";
CM_ SG_ 999 BCM_Status_Temp "GW ";
CM_ SG_ 999 BCM_T_BATT "GW ";
CM_ BO_ 1000 " ";
CM_ SG_ 1000 BCM_SOF_Q_STATE "GW ";
CM_ SG_ 1000 BCM_SOF_Q "GW ";
BA_DEF_  "BusType" STRING ;
BA_DEF_ SG_  "GenSigSendType" ENUM  "Cyclic","OnWrite","OnWriteWithRepetition","OnChange","OnChangeWithRepetition","IfActive","IfActiveWithRepetition","NoSigSendType","NotUsed","NotUsed","NotUsed","NotUsed","NotUsed";
BA_DEF_ SG_  "GenSigCycleTime" INT 0 0;
BA_DEF_ SG_  "GenSigInvalidValue" STRING ;
BA_DEF_ SG_  "GenSigStartValue" INT 0 0;
BA_DEF_ BO_  "VFrameFormat" ENUM  "StandardCAN","ExtendedCAN","reserved","reserved","reserved","reserved","reserved","reserved","reserved","reserved","reserved","reserved","reserved","reserved","StandardCAN_FD","ExtendedCAN_FD";
BA_DEF_ BO_  "CANFD_BRS" ENUM  "0","1";
BA_DEF_ BO_  "GenMsgCycleTime" INT 0 65535;
BA_DEF_ BO_  "GenMsgILSupport" ENUM  "No","Yes";
BA_DEF_ BO_  "GenMsgSendType" ENUM  "Cyclic","Event","NotUsed","NotUsed","NotUsed","Cyclic","NotUsed","IfActive","NoMsgSendType","NotUsed";
BA_DEF_ BU_  "ILUsed" ENUM  "No","Yes";
BA_DEF_ BU_  "NodeLayerModules" STRING ;
BA_DEF_DEF_  "BusType" "";
BA_DEF_DEF_  "GenSigSendType" "Cyclic";
BA_DEF_DEF_  "GenSigCycleTime" 0;
BA_DEF_DEF_  "GenSigInvalidValue" "/";
BA_DEF_DEF_  "GenSigStartValue" 0;
BA_DEF_DEF_  "VFrameFormat" "StandardCAN";
BA_DEF_DEF_  "CANFD_BRS" "1";
BA_DEF_DEF_  "GenMsgCycleTime" 0;
BA_DEF_DEF_  "GenMsgILSupport" "Yes";
BA_DEF_DEF_  "GenMsgSendType" "NoMsgSendType";
BA_DEF_DEF_  "ILUsed" "Yes";
BA_DEF_DEF_  "NodeLayerModules" "OSEKNM01.dll,CANoeILNLVector.dll";
BA_ "BusType" "CAN";
BA_ "VFrameFormat" BO_ 1874 14;
BA_ "VFrameFormat" BO_ 1882 14;
BA_ "GenMsgSendType" BO_ 80 0;
BA_ "GenMsgCycleTime" BO_ 80 500;
BA_ "VFrameFormat" BO_ 80 14;
BA_ "GenMsgSendType" BO_ 384 0;
BA_ "GenMsgCycleTime" BO_ 384 10;
BA_ "VFrameFormat" BO_ 384 14;
BA_ "GenMsgSendType" BO_ 391 0;
BA_ "GenMsgCycleTime" BO_ 391 10;
BA_ "VFrameFormat" BO_ 391 14;
BA_ "GenMsgSendType" BO_ 392 0;
BA_ "GenMsgCycleTime" BO_ 392 10;
BA_ "VFrameFormat" BO_ 392 14;
BA_ "GenMsgSendType" BO_ 406 0;
BA_ "GenMsgCycleTime" BO_ 406 10;
BA_ "VFrameFormat" BO_ 406 14;
BA_ "GenMsgSendType" BO_ 518 0;
BA_ "GenMsgCycleTime" BO_ 518 20;
BA_ "VFrameFormat" BO_ 518 14;
BA_ "GenMsgSendType" BO_ 520 0;
BA_ "GenMsgCycleTime" BO_ 520 20;
BA_ "VFrameFormat" BO_ 520 14;
BA_ "GenMsgSendType" BO_ 600 0;
BA_ "GenMsgCycleTime" BO_ 600 20;
BA_ "VFrameFormat" BO_ 600 14;
BA_ "GenMsgSendType" BO_ 631 0;
BA_ "GenMsgCycleTime" BO_ 631 20;
BA_ "VFrameFormat" BO_ 631 14;
BA_ "GenMsgSendType" BO_ 632 0;
BA_ "GenMsgCycleTime" BO_ 632 20;
BA_ "VFrameFormat" BO_ 632 14;
BA_ "GenMsgSendType" BO_ 832 0;
BA_ "GenMsgCycleTime" BO_ 832 100;
BA_ "VFrameFormat" BO_ 832 14;
BA_ "GenMsgSendType" BO_ 870 0;
BA_ "GenMsgCycleTime" BO_ 870 100;
BA_ "VFrameFormat" BO_ 870 14;
BA_ "GenMsgSendType" BO_ 903 0;
BA_ "GenMsgCycleTime" BO_ 903 100;
BA_ "VFrameFormat" BO_ 903 14;
BA_ "GenMsgSendType" BO_ 912 0;
BA_ "GenMsgCycleTime" BO_ 912 500;
BA_ "VFrameFormat" BO_ 912 14;
BA_ "GenMsgSendType" BO_ 1280 0;
BA_ "GenMsgCycleTime" BO_ 1280 1000;
BA_ "VFrameFormat" BO_ 1280 14;
BA_ "GenMsgSendType" BO_ 1281 0;
BA_ "GenMsgCycleTime" BO_ 1281 1000;
BA_ "VFrameFormat" BO_ 1281 14;
BA_ "GenMsgSendType" BO_ 1300 1;
BA_ "VFrameFormat" BO_ 1300 14;
BA_ "GenMsgSendType" BO_ 1328 0;
BA_ "GenMsgCycleTime" BO_ 1328 500;
BA_ "VFrameFormat" BO_ 1328 14;
BA_ "GenMsgSendType" BO_ 422 0;
BA_ "GenMsgCycleTime" BO_ 422 10;
BA_ "VFrameFormat" BO_ 422 14;
BA_ "GenMsgSendType" BO_ 424 0;
BA_ "GenMsgCycleTime" BO_ 424 10;
BA_ "VFrameFormat" BO_ 424 14;
BA_ "GenMsgSendType" BO_ 591 0;
BA_ "GenMsgCycleTime" BO_ 591 20;
BA_ "VFrameFormat" BO_ 591 14;
BA_ "GenMsgSendType" BO_ 651 0;
BA_ "GenMsgCycleTime" BO_ 651 40;
BA_ "VFrameFormat" BO_ 651 14;
BA_ "GenMsgSendType" BO_ 943 0;
BA_ "GenMsgCycleTime" BO_ 943 100;
BA_ "VFrameFormat" BO_ 943 14;
BA_ "GenMsgSendType" BO_ 952 0;
BA_ "GenMsgCycleTime" BO_ 952 100;
BA_ "VFrameFormat" BO_ 952 14;
BA_ "GenMsgSendType" BO_ 1023 0;
BA_ "GenMsgCycleTime" BO_ 1023 100;
BA_ "VFrameFormat" BO_ 1023 14;
BA_ "GenMsgSendType" BO_ 583 0;
BA_ "GenMsgCycleTime" BO_ 583 20;
BA_ "VFrameFormat" BO_ 583 14;
BA_ "GenMsgSendType" BO_ 746 0;
BA_ "GenMsgCycleTime" BO_ 746 50;
BA_ "VFrameFormat" BO_ 746 14;
BA_ "GenMsgSendType" BO_ 922 0;
BA_ "GenMsgCycleTime" BO_ 922 100;
BA_ "VFrameFormat" BO_ 922 14;
BA_ "GenMsgSendType" BO_ 1684 0;
BA_ "GenMsgCycleTime" BO_ 1684 500;
BA_ "VFrameFormat" BO_ 1684 14;
BA_ "GenMsgSendType" BO_ 999 0;
BA_ "GenMsgCycleTime" BO_ 999 100;
BA_ "VFrameFormat" BO_ 999 14;
BA_ "GenMsgSendType" BO_ 1000 0;
BA_ "GenMsgCycleTime" BO_ 1000 100;
BA_ "VFrameFormat" BO_ 1000 14;
BA_ "GenSigCycleTime" SG_ 80 SRS_PassengerBuckleSwitchStatus 500;
BA_ "GenSigCycleTime" SG_ 80 SRS_WarningLampStatus 500;
BA_ "GenSigCycleTime" SG_ 80 SRS_DriverBuckleSwitchStatus 500;
BA_ "GenSigCycleTime" SG_ 80 SRS_RollingCounter_id050 500;
BA_ "GenSigCycleTime" SG_ 80 SRS_CrashOutputStatusCheckSum 500;
BA_ "GenSigCycleTime" SG_ 80 SRS_CrashOutputStatus 500;
BA_ "GenSigCycleTime" SG_ 384 SAS_CRCCheck 10;
BA_ "GenSigCycleTime" SG_ 384 SAS_RollingCounter 10;
BA_ "GenSigCycleTime" SG_ 384 SAS_TrimmingSts 10;
BA_ "GenSigInvalidValue" SG_ 384 SAS_SteeringAngleSpeed "255";
BA_ "GenSigCycleTime" SG_ 384 SAS_SteeringAngleSpeed 10;
BA_ "GenSigStartValue" SG_ 384 SAS_SteeringAngle 32767;
BA_ "GenSigInvalidValue" SG_ 384 SAS_SteeringAngle "32767";
BA_ "GenSigCycleTime" SG_ 384 SAS_SteeringAngle 10;
BA_ "GenSigInvalidValue" SG_ 384 SAS_SASFailure "1";
BA_ "GenSigCycleTime" SG_ 384 SAS_SASFailure 10;
BA_ "GenSigInvalidValue" SG_ 384 SAS_Calibrated "LastValue";
BA_ "GenSigCycleTime" SG_ 384 SAS_Calibrated 10;
BA_ "GenSigInvalidValue" SG_ 384 SAS_SteeringAngleValid "1";
BA_ "GenSigCycleTime" SG_ 384 SAS_SteeringAngleValid 10;
BA_ "GenSigCycleTime" SG_ 391 ESP_ABSFailStatus 10;
BA_ "GenSigStartValue" SG_ 391 ESP_ESPFunctionStatus 1;
BA_ "GenSigCycleTime" SG_ 391 ESP_ESPFunctionStatus 10;
BA_ "GenSigCycleTime" SG_ 391 ESP_TCSFailStatus 10;
BA_ "GenSigInvalidValue" SG_ 391 ESP_VehicleSpeed "8191";
BA_ "GenSigCycleTime" SG_ 391 ESP_VehicleSpeed 10;
BA_ "GenSigInvalidValue" SG_ 391 ESP_VehicleSpeedValid "1";
BA_ "GenSigCycleTime" SG_ 391 ESP_VehicleSpeedValid 10;
BA_ "GenSigCycleTime" SG_ 391 ESP_ESPActiveStatus 10;
BA_ "GenSigCycleTime" SG_ 391 ESP_CRCCheck_187 10;
BA_ "GenSigCycleTime" SG_ 391 ESP_RollingCounter_187 10;
BA_ "GenSigInvalidValue" SG_ 392 TCU_ShiftinProgressValid "1";
BA_ "GenSigCycleTime" SG_ 392 TCU_ShiftinProgressValid 10;
BA_ "GenSigCycleTime" SG_ 392 TCU_ShiftinProgress 10;
BA_ "GenSigCycleTime" SG_ 392 TCU_CRCCheck_188 10;
BA_ "GenSigCycleTime" SG_ 392 TCU_RollingCounter_188 10;
BA_ "GenSigInvalidValue" SG_ 406 EMS_AccPedal "255";
BA_ "GenSigCycleTime" SG_ 406 EMS_AccPedal 10;
BA_ "GenSigInvalidValue" SG_ 406 EMS_EngineSpeed "65535";
BA_ "GenSigCycleTime" SG_ 406 EMS_EngineSpeed 10;
BA_ "GenSigInvalidValue" SG_ 518 Wheel_Speed_FL_Data "8191";
BA_ "GenSigCycleTime" SG_ 518 Wheel_Speed_FL_Data 20;
BA_ "GenSigInvalidValue" SG_ 518 Wheel_Speed_FR_Data "8191";
BA_ "GenSigCycleTime" SG_ 518 Wheel_Speed_FR_Data 20;
BA_ "GenSigInvalidValue" SG_ 518 Wheel_Speed_FL_Valid_Data "1";
BA_ "GenSigCycleTime" SG_ 518 Wheel_Speed_FL_Valid_Data 20;
BA_ "GenSigInvalidValue" SG_ 518 Wheel_Speed_FR_Valid_Data "1";
BA_ "GenSigCycleTime" SG_ 518 Wheel_Speed_FR_Valid_Data 20;
BA_ "GenSigInvalidValue" SG_ 518 Wheel_Speed_FL_Direction "3";
BA_ "GenSigCycleTime" SG_ 518 Wheel_Speed_FL_Direction 20;
BA_ "GenSigInvalidValue" SG_ 518 Wheel_Speed_FR_Direction "3";
BA_ "GenSigCycleTime" SG_ 518 Wheel_Speed_FR_Direction 20;
BA_ "GenSigCycleTime" SG_ 518 ESP_CRCCheck_206 20;
BA_ "GenSigCycleTime" SG_ 518 ESP_RollingCounter_206 20;
BA_ "GenSigInvalidValue" SG_ 520 Wheel_Speed_RL_Data "8191";
BA_ "GenSigCycleTime" SG_ 520 Wheel_Speed_RL_Data 20;
BA_ "GenSigInvalidValue" SG_ 520 Wheel_Speed_RR_Data "8191";
BA_ "GenSigCycleTime" SG_ 520 Wheel_Speed_RR_Data 20;
BA_ "GenSigInvalidValue" SG_ 520 Wheel_Speed_RL_Valid_Data "1";
BA_ "GenSigCycleTime" SG_ 520 Wheel_Speed_RL_Valid_Data 20;
BA_ "GenSigInvalidValue" SG_ 520 Wheel_Speed_RR_Valid_Data "1";
BA_ "GenSigCycleTime" SG_ 520 Wheel_Speed_RR_Valid_Data 20;
BA_ "GenSigInvalidValue" SG_ 520 Wheel_Speed_RL_Direction "3";
BA_ "GenSigCycleTime" SG_ 520 Wheel_Speed_RL_Direction 20;
BA_ "GenSigCycleTime" SG_ 520 Wheel_Speed_RR_Direction 20;
BA_ "GenSigCycleTime" SG_ 520 ESP_CRCCheck_208 20;
BA_ "GenSigCycleTime" SG_ 520 ESP_RollingCounter_208 20;
BA_ "GenSigInvalidValue" SG_ 600 ESP_MasCylBrakePressure "4095";
BA_ "GenSigCycleTime" SG_ 600 ESP_MasCylBrakePressure 20;
BA_ "GenSigCycleTime" SG_ 600 ESP_MasCylBrakePressureValid 20;
BA_ "GenSigInvalidValue" SG_ 600 Wheel_Speed_FL_Pulse "255";
BA_ "GenSigCycleTime" SG_ 600 Wheel_Speed_FL_Pulse 20;
BA_ "GenSigInvalidValue" SG_ 600 Wheel_Speed_FR_Pulse "255";
BA_ "GenSigCycleTime" SG_ 600 Wheel_Speed_FR_Pulse 20;
BA_ "GenSigInvalidValue" SG_ 600 Wheel_Speed_RL_Pulse "255";
BA_ "GenSigCycleTime" SG_ 600 Wheel_Speed_RL_Pulse 20;
BA_ "GenSigInvalidValue" SG_ 600 Wheel_Speed_RR_Pulse "255";
BA_ "GenSigCycleTime" SG_ 600 Wheel_Speed_RR_Pulse 20;
BA_ "GenSigCycleTime" SG_ 600 ESP_RollingCounter_258 20;
BA_ "GenSigCycleTime" SG_ 600 ESP_CRCCheck_258 20;
BA_ "GenSigCycleTime" SG_ 631 ESP_CRCCheck_277 20;
BA_ "GenSigCycleTime" SG_ 631 ESP_RollingCounter_277 20;
BA_ "GenSigCycleTime" SG_ 631 ESP_VehicleStandstill 20;
BA_ "GenSigCycleTime" SG_ 631 ESP_BrakeForce 20;
BA_ "GenSigCycleTime" SG_ 632 ESP_YawRateValid 20;
BA_ "GenSigInvalidValue" SG_ 632 ESP_YawRate "16383";
BA_ "GenSigCycleTime" SG_ 632 ESP_YawRate 20;
BA_ "GenSigCycleTime" SG_ 632 ESP_CRCCheck_278 20;
BA_ "GenSigCycleTime" SG_ 632 ESP_RollingCounter_278 20;
BA_ "GenSigInvalidValue" SG_ 632 ESP_LongAccel "1023";
BA_ "GenSigCycleTime" SG_ 632 ESP_LongAccel 20;
BA_ "GenSigInvalidValue" SG_ 632 ESP_LatAccel "255";
BA_ "GenSigCycleTime" SG_ 632 ESP_LatAccel 20;
BA_ "GenSigInvalidValue" SG_ 832 AC_FrBlowType "7";
BA_ "GenSigCycleTime" SG_ 832 AC_FrBlowType 100;
BA_ "GenSigStartValue" SG_ 870 AC_EnvironmentalTemp 255;
BA_ "GenSigInvalidValue" SG_ 870 AC_EnvironmentalTemp "255";
BA_ "GenSigCycleTime" SG_ 870 AC_EnvironmentalTemp 100;
BA_ "GenSigInvalidValue" SG_ 870 AC_EnvironmentalTempVD "1";
BA_ "GenSigCycleTime" SG_ 870 AC_EnvironmentalTempVD 100;
BA_ "GenSigStartValue" SG_ 903 BCM_RainfallLevel 14;
BA_ "GenSigInvalidValue" SG_ 903 BCM_RainfallLevel "15";
BA_ "GenSigCycleTime" SG_ 903 BCM_RainfallLevel 200;
BA_ "GenSigInvalidValue" SG_ 903 BCM_FrontWiperStatus "3";
BA_ "GenSigCycleTime" SG_ 903 BCM_FrontWiperStatus 100;
BA_ "GenSigStartValue" SG_ 912 BCM_SOH_LifePercent 100;
BA_ "GenSigInvalidValue" SG_ 912 BCM_SOH_LifePercent "255";
BA_ "GenSigCycleTime" SG_ 912 BCM_SOH_LifePercent 500;
BA_ "GenSigCycleTime" SG_ 912 BCM_PMSLevel 500;
BA_ "GenSigInvalidValue" SG_ 1280 HU_CurrentLocationLatitude "268435455";
BA_ "GenSigCycleTime" SG_ 1280 HU_CurrentLocationLatitude 1000;
BA_ "GenSigInvalidValue" SG_ 1280 HU_CurrentLocationLongitude "536870911";
BA_ "GenSigCycleTime" SG_ 1280 HU_CurrentLocationLongitude 1000;
BA_ "GenSigInvalidValue" SG_ 1281 HU_LocalTimeSecond "0";
BA_ "GenSigCycleTime" SG_ 1281 HU_LocalTimeSecond 1000;
BA_ "GenSigInvalidValue" SG_ 1281 HU_LocalTimeMinute "0";
BA_ "GenSigCycleTime" SG_ 1281 HU_LocalTimeMinute 1000;
BA_ "GenSigInvalidValue" SG_ 1281 HU_LocalTimeHour "0";
BA_ "GenSigCycleTime" SG_ 1281 HU_LocalTimeHour 1000;
BA_ "GenSigStartValue" SG_ 1281 HU_LocalTimeDate 1;
BA_ "GenSigInvalidValue" SG_ 1281 HU_LocalTimeDate "1";
BA_ "GenSigCycleTime" SG_ 1281 HU_LocalTimeDate 1000;
BA_ "GenSigInvalidValue" SG_ 1281 HU_LocalTimeYear "0";
BA_ "GenSigCycleTime" SG_ 1281 HU_LocalTimeYear 1000;
BA_ "GenSigStartValue" SG_ 1281 HU_LocalTimeMonth 1;
BA_ "GenSigInvalidValue" SG_ 1281 HU_LocalTimeMonth "1";
BA_ "GenSigCycleTime" SG_ 1281 HU_LocalTimeMonth 1000;
BA_ "GenSigInvalidValue" SG_ 1281 HU_LocalTimeValid "1";
BA_ "GenSigCycleTime" SG_ 1281 HU_LocalTimeValid 1000;
BA_ "GenSigInvalidValue" SG_ 1328 IP_TotalOdometer "16777215";
BA_ "GenSigCycleTime" SG_ 1328 IP_TotalOdometer 500;
BA_ "GenSigCycleTime" SG_ 422 EMS_CRCCheck_1A6 10;
BA_ "GenSigCycleTime" SG_ 422 EMS_RollingCounter_1A6 10;
BA_ "GenSigCycleTime" SG_ 422 EMS_EngineStatus 10;
BA_ "GenSigInvalidValue" SG_ 424 TCU_ActualGear "15";
BA_ "GenSigCycleTime" SG_ 424 TCU_ActualGear 10;
BA_ "GenSigInvalidValue" SG_ 424 TCU_ActualGearValid "1";
BA_ "GenSigCycleTime" SG_ 424 TCU_ActualGearValid 10;
BA_ "GenSigStartValue" SG_ 424 TCU_GearShiftPosition 14;
BA_ "GenSigInvalidValue" SG_ 424 TCU_GearShiftPosition "15";
BA_ "GenSigCycleTime" SG_ 424 TCU_GearShiftPosition 10;
BA_ "GenSigInvalidValue" SG_ 424 TCU_ShiftPostionValid "1";
BA_ "GenSigCycleTime" SG_ 424 TCU_ShiftPostionValid 10;
BA_ "GenSigCycleTime" SG_ 424 TCU_CRCCheck_1A8 10;
BA_ "GenSigCycleTime" SG_ 424 TCU_RollingCounter_1A8 10;
BA_ "GenSigInvalidValue" SG_ 591 EPS_ConcussAvailabilityStatus "2";
BA_ "GenSigCycleTime" SG_ 591 EPS_ConcussAvailabilityStatus 20;
BA_ "GenSigStartValue" SG_ 591 EPS_TorqueAssistMode 3;
BA_ "GenSigCycleTime" SG_ 591 EPS_TorqueAssistMode 20;
BA_ "GenSigCycleTime" SG_ 591 EPS_IACC_abortreason 20;
BA_ "GenSigCycleTime" SG_ 591 EPS_CRCCheck_24F 20;
BA_ "GenSigCycleTime" SG_ 591 EPS_RollingCounter_24F 20;
BA_ "GenSigInvalidValue" SG_ 651 LCM_LASSwitch "3";
BA_ "GenSigCycleTime" SG_ 651 LCM_LASSwitch 40;
BA_ "GenSigInvalidValue" SG_ 651 BCM_TurnIndicatorLeft "3";
BA_ "GenSigCycleTime" SG_ 651 BCM_TurnIndicatorLeft 40;
BA_ "GenSigInvalidValue" SG_ 651 BCM_TurnIndicatorRight "3";
BA_ "GenSigCycleTime" SG_ 651 BCM_TurnIndicatorRight 40;
BA_ "GenSigInvalidValue" SG_ 651 BCM_emergencylightstatus "3";
BA_ "GenSigCycleTime" SG_ 651 BCM_emergencylightstatus 40;
BA_ "GenSigInvalidValue" SG_ 651 BCM_LowBeamStatus "3";
BA_ "GenSigCycleTime" SG_ 651 BCM_LowBeamStatus 40;
BA_ "GenSigInvalidValue" SG_ 651 BCM_HighBeamStatus "3";
BA_ "GenSigCycleTime" SG_ 651 BCM_HighBeamStatus 40;
BA_ "GenSigInvalidValue" SG_ 651 BCM_TurnLightSwitchSts "3";
BA_ "GenSigCycleTime" SG_ 651 BCM_TurnLightSwitchSts 40;
BA_ "GenSigCycleTime" SG_ 943 HU_CRCCheck_3AF 100;
BA_ "GenSigCycleTime" SG_ 943 HU_RollingCounter_3AF 100;
BA_ "GenSigStartValue" SG_ 943 HU_RampDistance 63;
BA_ "GenSigInvalidValue" SG_ 943 HU_RampDistance "63";
BA_ "GenSigCycleTime" SG_ 943 HU_RampDistance 100;
BA_ "GenSigInvalidValue" SG_ 943 HU_NavSpeedLimitType "0";
BA_ "GenSigCycleTime" SG_ 943 HU_NavSpeedLimitType 100;
BA_ "GenSigStartValue" SG_ 943 HU_CurveDistance 63;
BA_ "GenSigInvalidValue" SG_ 943 HU_CurveDistance "63";
BA_ "GenSigCycleTime" SG_ 943 HU_CurveDistance 100;
BA_ "GenSigInvalidValue" SG_ 943 HU_EnterCurveInfo "0";
BA_ "GenSigCycleTime" SG_ 943 HU_EnterCurveInfo 100;
BA_ "GenSigInvalidValue" SG_ 943 HU_NavCurrentRoadType "0";
BA_ "GenSigCycleTime" SG_ 943 HU_NavCurrentRoadType 100;
BA_ "GenSigInvalidValue" SG_ 943 HU_EnterRampInfo "0";
BA_ "GenSigCycleTime" SG_ 943 HU_EnterRampInfo 100;
BA_ "GenSigInvalidValue" SG_ 943 HU_RampInfo "0";
BA_ "GenSigCycleTime" SG_ 943 HU_RampInfo 100;
BA_ "GenSigInvalidValue" SG_ 943 HU_NavCountryCode "0";
BA_ "GenSigCycleTime" SG_ 943 HU_NavCountryCode 100;
BA_ "GenSigInvalidValue" SG_ 943 HU_NavStatus "1";
BA_ "GenSigCycleTime" SG_ 943 HU_NavStatus 100;
BA_ "GenSigInvalidValue" SG_ 943 HU_NavSpeedLimitUnits "0";
BA_ "GenSigCycleTime" SG_ 943 HU_NavSpeedLimitUnits 100;
BA_ "GenSigInvalidValue" SG_ 943 HU_NavSpeedLimitStatus "1";
BA_ "GenSigCycleTime" SG_ 943 HU_NavSpeedLimitStatus 100;
BA_ "GenSigStartValue" SG_ 943 HU_NavSpeedLimit 254;
BA_ "GenSigInvalidValue" SG_ 943 HU_NavSpeedLimit "255";
BA_ "GenSigCycleTime" SG_ 943 HU_NavSpeedLimit 100;
BA_ "GenSigCycleTime" SG_ 952 HU_CRCCheck_3B8 100;
BA_ "GenSigCycleTime" SG_ 952 HU_RollingCounter_3B8 100;
BA_ "GenSigInvalidValue" SG_ 952 HU_NavGuiganceStatus "3";
BA_ "GenSigCycleTime" SG_ 952 HU_NavGuiganceStatus 100;
BA_ "GenSigStartValue" SG_ 952 HU_SlopeDistance 63;
BA_ "GenSigInvalidValue" SG_ 952 HU_SlopeDistance "63";
BA_ "GenSigCycleTime" SG_ 952 HU_SlopeDistance 100;
BA_ "GenSigInvalidValue" SG_ 952 HU_Byroad "3";
BA_ "GenSigCycleTime" SG_ 952 HU_Byroad 100;
BA_ "GenSigStartValue" SG_ 952 HU_TunnelLength 63;
BA_ "GenSigInvalidValue" SG_ 952 HU_TunnelLength "63";
BA_ "GenSigCycleTime" SG_ 952 HU_TunnelLength 100;
BA_ "GenSigStartValue" SG_ 952 HU_RoadCurvatureFar 511;
BA_ "GenSigInvalidValue" SG_ 952 HU_RoadCurvatureFar "1023";
BA_ "GenSigCycleTime" SG_ 952 HU_RoadCurvatureFar 100;
BA_ "GenSigStartValue" SG_ 952 HU_TunnelDistance 63;
BA_ "GenSigInvalidValue" SG_ 952 HU_TunnelDistance "63";
BA_ "GenSigCycleTime" SG_ 952 HU_TunnelDistance 100;
BA_ "GenSigStartValue" SG_ 952 HU_RoadCurvature 511;
BA_ "GenSigInvalidValue" SG_ 952 HU_RoadCurvature "1023";
BA_ "GenSigCycleTime" SG_ 952 HU_RoadCurvature 100;
BA_ "GenSigInvalidValue" SG_ 952 HU_EnterSlopeInfo "0";
BA_ "GenSigCycleTime" SG_ 952 HU_EnterSlopeInfo 100;
BA_ "GenSigInvalidValue" SG_ 952 HU_EnterTunnelInfo "0";
BA_ "GenSigCycleTime" SG_ 952 HU_EnterTunnelInfo 100;
BA_ "GenSigInvalidValue" SG_ 1023 BCM_AutoHeadlightSts "0";
BA_ "GenSigCycleTime" SG_ 1023 BCM_AutoHeadlightSts 100;
BA_ "GenSigInvalidValue" SG_ 1023 BCM_FrontFoglampStatus "3";
BA_ "GenSigCycleTime" SG_ 1023 BCM_FrontFoglampStatus 100;
BA_ "GenSigInvalidValue" SG_ 1023 BCM_RearFoglampStatus "3";
BA_ "GenSigCycleTime" SG_ 1023 BCM_RearFoglampStatus 100;
BA_ "GenSigCycleTime" SG_ 583 APA_APAOnOff 20;
BA_ "GenSigInvalidValue" SG_ 746 ADS_LCDAR_BSD_LCAStatus "3";
BA_ "GenSigCycleTime" SG_ 746 ADS_LCDAR_BSD_LCAStatus 50;
BA_ "GenSigInvalidValue" SG_ 746 ADS_LCDAR_Left_BSD_LCAStatus "3";
BA_ "GenSigCycleTime" SG_ 746 ADS_LCDAR_Left_BSD_LCAStatus 50;
BA_ "GenSigInvalidValue" SG_ 922 LAS_TSRRightLaneStatus "7";
BA_ "GenSigCycleTime" SG_ 922 LAS_TSRRightLaneStatus 100;
BA_ "GenSigInvalidValue" SG_ 922 LAS_TSRLeftLaneStatus "7";
BA_ "GenSigCycleTime" SG_ 922 LAS_TSRLeftLaneStatus 100;
BA_ "GenSigCycleTime" SG_ 922 LAS_CRCCheck_3C0 100;
BA_ "GenSigCycleTime" SG_ 922 LAS_RollingCounter_3C0 100;
BA_ "GenSigInvalidValue" SG_ 922 LAS_TSRRightLaneSpdLimit "254";
BA_ "GenSigCycleTime" SG_ 922 LAS_TSRRightLaneSpdLimit 100;
BA_ "GenSigInvalidValue" SG_ 922 LAS_TSRLeftLaneSpdLimit "254";
BA_ "GenSigCycleTime" SG_ 922 LAS_TSRLeftLaneSpdLimit 100;
BA_ "GenSigCycleTime" SG_ 922 LAS_CRCCheck_3D4 100;
BA_ "GenSigCycleTime" SG_ 922 LAS_RollingCounter_3D4 100;
BA_ "GenSigStartValue" SG_ 922 LAS_TLAStopLine_HostLane 255;
BA_ "GenSigCycleTime" SG_ 922 LAS_TLAStopLine_HostLane 100;
BA_ "GenSigStartValue" SG_ 922 LAS_TLADistance_HostLane 255;
BA_ "GenSigCycleTime" SG_ 922 LAS_TLADistance_HostLane 100;
BA_ "GenSigCycleTime" SG_ 922 LAS_TLACountDownTime_HostLane 100;
BA_ "GenSigCycleTime" SG_ 922 LAS_TSRMandatorySign 100;
BA_ "GenSigCycleTime" SG_ 922 LAS_TSRWarningSign 100;
BA_ "GenSigCycleTime" SG_ 922 LAS_TSRProhibitionSign 100;
BA_ "GenSigCycleTime" SG_ 922 LAS_CRCCheck_332 100;
BA_ "GenSigCycleTime" SG_ 922 LAS_RollingCounter_332 100;
BA_ "GenSigCycleTime" SG_ 922 LAS_OverspeedSoundWarningEnSt 100;
BA_ "GenSigCycleTime" SG_ 922 LAS_TSREnable 100;
BA_ "GenSigCycleTime" SG_ 922 LAS_HMAEnableStatus 100;
BA_ "GenSigCycleTime" SG_ 922 LAS_HMALightDistribution 100;
BA_ "GenSigInvalidValue" SG_ 922 LAS_HMAStatus "3";
BA_ "GenSigCycleTime" SG_ 922 LAS_HMAStatus 100;
BA_ "GenSigInvalidValue" SG_ 922 LAS_TSRHostSpdLimitUnits "0";
BA_ "GenSigCycleTime" SG_ 922 LAS_TSRHostSpdLimitUnits 100;
BA_ "GenSigInvalidValue" SG_ 922 LAS_TSRHostSpdLimit "254";
BA_ "GenSigCycleTime" SG_ 922 LAS_TSRHostSpdLimit 100;
BA_ "GenSigInvalidValue" SG_ 922 LAS_TSRStatus "7";
BA_ "GenSigCycleTime" SG_ 922 LAS_TSRStatus 100;
BA_ "GenSigInvalidValue" SG_ 922 LAS_FrontCameraCalibrationStatus "3";
BA_ "GenSigCycleTime" SG_ 922 LAS_FrontCameraCalibrationStatus 100;
BA_ "GenSigInvalidValue" SG_ 922 LAS_FrontCameraFailureStatus "3";
BA_ "GenSigCycleTime" SG_ 922 LAS_FrontCameraFailureStatus 100;
BA_ "GenSigStartValue" SG_ 922 LAS_OverspeedWarningOffset 20;
BA_ "GenSigCycleTime" SG_ 922 LAS_OverspeedWarningOffset 100;
BA_ "GenSigCycleTime" SG_ 922 LAS_OverspeedWarningEnableStatus 100;
BA_ "GenSigCycleTime" SG_ 922 LAS_OverspeedSoundWarning 100;
BA_ "GenSigCycleTime" SG_ 922 LAS_OverspeedVisualWarning 100;
BA_ "GenSigCycleTime" SG_ 922 LAS_CRCCheck_37D 100;
BA_ "GenSigCycleTime" SG_ 922 LAS_RollingCounter_37D 100;
BA_ "GenSigCycleTime" SG_ 922 LAS_TLAArrowDirection_RightLane 100;
BA_ "GenSigCycleTime" SG_ 922 LAS_TLAObjectType_RightLane 100;
BA_ "GenSigCycleTime" SG_ 922 LAS_TLAObjectStatus_RightLane 100;
BA_ "GenSigCycleTime" SG_ 922 LAS_TLAObjectColour_RightLane 100;
BA_ "GenSigCycleTime" SG_ 922 LAS_TLAObjectDetection_RightLane 100;
BA_ "GenSigCycleTime" SG_ 922 LAS_TLAArrowDirection_LeftLane 100;
BA_ "GenSigCycleTime" SG_ 922 LAS_TLAObjectType_LeftLane 100;
BA_ "GenSigCycleTime" SG_ 922 LAS_TLAObjectStatus_LeftLane 100;
BA_ "GenSigCycleTime" SG_ 922 LAS_TLAObjectColour_LeftLane 100;
BA_ "GenSigCycleTime" SG_ 922 LAS_TLAObjectDetection_LeftLane 100;
BA_ "GenSigCycleTime" SG_ 922 LAS_TLAArrowDirection_HostLane 100;
BA_ "GenSigCycleTime" SG_ 922 LAS_TLAObjectStatus_HostLane 100;
BA_ "GenSigCycleTime" SG_ 922 LAS_TLAObjectType_HostLane 100;
BA_ "GenSigCycleTime" SG_ 922 LAS_TLAObjectColour_HostLane 100;
BA_ "GenSigCycleTime" SG_ 922 LAS_TLAObjectDetection_HostLane 100;
BA_ "GenSigCycleTime" SG_ 922 LAS_TLAWarninglevel 100;
BA_ "GenSigInvalidValue" SG_ 922 LAS_TLAStatus "3";
BA_ "GenSigCycleTime" SG_ 922 LAS_TLAStatus 100;
BA_ "GenSigCycleTime" SG_ 922 LAS_TLAEnable 100;
BA_ "GenSigCycleTime" SG_ 1684 LAS_DTC2_Status 500;
BA_ "GenSigCycleTime" SG_ 1684 LAS_DTC2_LowByte 500;
BA_ "GenSigCycleTime" SG_ 1684 LAS_DTC2_MiddByte 500;
BA_ "GenSigCycleTime" SG_ 1684 LAS_DTC2_HighByte 500;
BA_ "GenSigCycleTime" SG_ 1684 LAS_DTC1_Status 500;
BA_ "GenSigCycleTime" SG_ 1684 LAS_DTC1_LowByte 500;
BA_ "GenSigCycleTime" SG_ 1684 LAS_DTC1_MiddByte 500;
BA_ "GenSigCycleTime" SG_ 1684 LAS_DTC1_HighByte 500;
BA_ "GenSigInvalidValue" SG_ 999 BCM_Status_Temp "0";
BA_ "GenSigCycleTime" SG_ 999 BCM_Status_Temp 100;
BA_ "GenSigStartValue" SG_ 999 BCM_T_BATT 255;
BA_ "GenSigInvalidValue" SG_ 999 BCM_T_BATT "255";
BA_ "GenSigCycleTime" SG_ 999 BCM_T_BATT 100;
BA_ "GenSigStartValue" SG_ 1000 BCM_SOF_Q_STATE 3;
BA_ "GenSigInvalidValue" SG_ 1000 BCM_SOF_Q_STATE "3";
BA_ "GenSigCycleTime" SG_ 1000 BCM_SOF_Q_STATE 100;
BA_ "GenSigStartValue" SG_ 1000 BCM_SOF_Q 255;
BA_ "GenSigInvalidValue" SG_ 1000 BCM_SOF_Q "255";
BA_ "GenSigCycleTime" SG_ 1000 BCM_SOF_Q 100;
VAL_ 80 SRS_PassengerBuckleSwitchStatus 0 "Buckled" 1 "Unbuckle " 2 "Not Used" 3 "Not Used
Default value: 0x0" ;
VAL_ 80 SRS_WarningLampStatus 0 "Lamp off" 1 "Lamp on" 2 "Lamp Flashing" 3 "Not Used" ;
VAL_ 80 SRS_DriverBuckleSwitchStatus 0 "Buckled" 1 "Unbuckle " 2 "Not Used" 3 "Not Used
Default value: 0x0" ;
VAL_ 80 SRS_CrashOutputStatusCheckSum 0 "(SRS_CrashOutputStatus) XOR 0xF" ;
VAL_ 80 SRS_CrashOutputStatus 0 "No Crash" 1 "crash " 2 "Not Used" ;
VAL_ 384 SAS_TrimmingSts 0 " Sensor not trimmed, this is handled as a sensor failure" 1 "Sensor trimmed" ;
VAL_ 384 SAS_SASFailure 0 "No Failure" 1 "Failure" ;
VAL_ 384 SAS_Calibrated 0 "Calibrated" 1 " Not Calibrated" ;
VAL_ 384 SAS_SteeringAngleValid 0 "Valid " 1 "Invalid" ;
VAL_ 391 ESP_ABSFailStatus 0 "Noerror" 1 "Error" ;
VAL_ 391 ESP_ESPFunctionStatus 0 "OFF" 1 "ON" ;
VAL_ 391 ESP_TCSFailStatus 0 "Noerror" 1 "Error" ;
VAL_ 391 ESP_VehicleSpeed 0 "0~360km/h" 6401 "Reserved" 8191 "Invalid
APA2.0" ;
VAL_ 391 ESP_VehicleSpeedValid 0 "Valid" 1 "NotValid" ;
VAL_ 391 ESP_ESPActiveStatus 0 "NotActive" 1 "Active" ;
VAL_ 392 TCU_ShiftinProgressValid 0 "Valid" 1 "Invalid" ;
VAL_ 392 TCU_ShiftinProgress 0 "Noshift" 1 "Shift" ;
VAL_ 406 EMS_EngineSpeed 0 "0~16383.5Rmp" 65535 "Invalid" ;
VAL_ 518 Wheel_Speed_FL_Valid_Data 0 "Valid" 1 "NotValid" ;
VAL_ 518 Wheel_Speed_FR_Valid_Data 0 "Valid" 1 "NotValid" ;
VAL_ 518 Wheel_Speed_FL_Direction 0 "Forward" 1 "backward" 2 "Standstill" 3 "Invalid" ;
VAL_ 518 Wheel_Speed_FR_Direction 0 "Forward" 1 "backward" 2 "Standstill" 3 "Invalid" ;
VAL_ 520 Wheel_Speed_RL_Valid_Data 0 "Valid" 1 "NotValid" ;
VAL_ 520 Wheel_Speed_RR_Valid_Data 0 "Valid" 1 "NotValid" ;
VAL_ 520 Wheel_Speed_RL_Direction 0 "Forward" 1 "backward" 2 "Standstill" 3 "Invalid" ;
VAL_ 520 Wheel_Speed_RR_Direction 0 "Forward" 1 "backward" 2 "Standstill" 3 "Invalid" ;
VAL_ 600 ESP_MasCylBrakePressure 4095 "invalid" ;
VAL_ 600 ESP_MasCylBrakePressureValid 0 "Valid" 1 "Invalid" ;
VAL_ 600 Wheel_Speed_FL_Pulse 255 "invalid" ;
VAL_ 600 Wheel_Speed_FR_Pulse 255 "invalid" ;
VAL_ 600 Wheel_Speed_RL_Pulse 255 "invalid" ;
VAL_ 600 Wheel_Speed_RR_Pulse 255 "invalid" ;
VAL_ 631 ESP_VehicleStandstill 0 "notstandstill" 1 "standstill" ;
VAL_ 631 ESP_BrakeForce 0 "nobrakeforce" 1 "havebrakeforce" ;
VAL_ 632 ESP_YawRateValid 0 "Valid" 1 "Invalid" ;
VAL_ 632 ESP_YawRate 16383 "invalid" ;
VAL_ 632 ESP_LongAccel 1023 "invalid" ;
VAL_ 632 ESP_LatAccel 255 "invalid" ;
VAL_ 832 AC_FrBlowType 6 "Reserved" 0 "blow face" 1 "blow face/blow feet" 2 "blow feet" 3 "blow fee/defroster" 4 "defroster" 5 "Reserved" 7 "Invalid." ;
VAL_ 870 AC_EnvironmentalTemp 0 "-40~87" 255 "Invalid" ;
VAL_ 870 AC_EnvironmentalTempVD 0 "Valid" 1 "Invalid" ;
VAL_ 903 BCM_RainfallLevel 0 "No rain" 1 "Level 1" 2 "Level 2" 3 "Level 3" 4 "Level 4" 5 "Level 5?" 6 "Level 6" 7 "Level 7" 8 "Level 8" 9 "Level 9" 10 "Level 10" 11 "Level 11" 12 "Level 12" 13 "level 13" 14 "init value" 15 "Invalid value" ;
VAL_ 903 BCM_FrontWiperStatus 0 "OFF" 1 "Low" 2 "High" 3 "Error" ;
VAL_ 912 BCM_SOH_LifePercent 0 "%0-100%" 101 "Reserved" 255 "invalid" ;
VAL_ 912 BCM_PMSLevel 0 "Normal Battery" 1 "Low battery" 2 "High battery" 3 "0x3-0x7: Reserved" ;
VAL_ 1280 HU_CurrentLocationLatitude 268435455 "invalid" 134217727 "" ;
VAL_ 1280 HU_CurrentLocationLongitude 536870911 "invalid" 268435455 "" ;
VAL_ 1281 HU_LocalTimeValid 0 "Valid" 1 "Not Valid" ;
VAL_ 1300 HU_IACCEnable 0 "Inactive" 1 "Off" 2 "On" 3 "Reserved" ;
VAL_ 1300 HU_HMAEnable 0 "off" 1 "on" ;
VAL_ 1300 HU_TSRSwitch 0 "off" 1 "on" ;
VAL_ 1300 HU_LASModeSelection 6 "Reserved" 5 "Reserved" 0 "Inactive" 1 "LDW" 2 "LKA" 3 "LCS" 4 "Reserved" 7 "OFF" ;
VAL_ 1300 HU_OverspeedWarningOffset 0 "0x0-0x14: -10-10km/h" 21 "0x15-0x1E: Reserved" 31 "Invalid." ;
VAL_ 1300 HU_OverspeedWarningEnable 0 "Inactive" 1 "OFF" 2 "ON" 3 "Reserved" ;
VAL_ 1300 HU_OverspeedSoundWarEnable 0 "Inactive" 1 "Off" 2 "On" 3 " Reserved" ;
VAL_ 1328 IP_TotalOdometer 16777215 "invalid" ;
VAL_ 422 EMS_EngineStatus 0 "Stop" 1 "Crank" 2 "Running" 3 "Reserved" ;
VAL_ 424 TCU_ActualGear 0 "Neutral" 1 "1stgear" 2 "2ndgear" 3 "3rdgear" 4 "4tgear" 5 "5tgear" 6 "6tgear" 7 "7tgear" 8 "8tgear" 9 "Reverse" 10 "Parking" 11 "Reserved" 12 "Reserved" 13 "Reserved" 14 "Reserved" 15 "Invalid" ;
VAL_ 424 TCU_ActualGearValid 0 "Valid" 1 "Invalid" ;
VAL_ 424 TCU_GearShiftPosition 0 "Parking" 1 "Reverse" 2 "Neutral" 3 "D" 4 "D3" 5 "D2" 6 "L" 7 "M_or_S" 8 "Reserved" 9 "Reserved" 10 "Reserved" 11 "Reserved" 12 "Reserved" 13 "Reserved" 14 "Unreliable" 15 "Invalid" ;
VAL_ 424 TCU_ShiftPostionValid 0 "Valid" 1 "Invalid" ;
VAL_ 591 EPS_ConcussAvailabilityStatus 0 "Concuss Availability " 1 "Concuss Active" 2 "EPS Concuss failure  " 3 "reserved" ;
VAL_ 591 EPS_TorqueAssistMode 0 "Normal" 1 "light" 2 "heavy" 3 "unknow" ;
VAL_ 591 EPS_IACC_abortreason 0 "NO_DRIVING_INTERUPTION" 1 "DRIVER_RECOVERY(Over ride)" 2 "VEHICLE_SPEED ERROR" 3 "REQUEST ERROR" 4 "DAE_THERMAL_SECURITY" 5 "OTHER_DEFAULT" ;
VAL_ 651 LCM_LASSwitch 0 "Not Push " 1 "Push " 2 "Reserved " 3 "Fault" ;
VAL_ 651 BCM_TurnIndicatorLeft 0 "OFF" 1 "ON" 2 "Not used" 3 "Error" ;
VAL_ 651 BCM_TurnIndicatorRight 0 "OFF" 1 "ON" 2 "Not used" 3 "Error" ;
VAL_ 651 BCM_emergencylightstatus 0 "OFF" 1 "ON" 2 "Not used" 3 "Error" ;
VAL_ 651 BCM_LowBeamStatus 0 "OFF" 1 "ON" 2 "Not used" 3 "Reserved" ;
VAL_ 651 BCM_HighBeamStatus 0 "OFF" 1 "ON" 2 "Not used" 3 "Reserved" ;
VAL_ 651 BCM_TurnLightSwitchSts 0 "Not Actived" 1 "Left Actived" 2 "Right Actived" 3 "Invalid" ;
VAL_ 943 HU_RampDistance 0 " 0~600m" 61 "Out of Range" 62 "reserved" 63 "unknown" ;
VAL_ 943 HU_NavSpeedLimitType 0 "Unknown" 1 "Speed-Limit Sign" 2 "Road Camera" 3 "Reserved" ;
VAL_ 943 HU_CurveDistance 0 " 0~600m" 61 "Out of Range" 62 "reserved" 63 "unknown" ;
VAL_ 943 HU_EnterCurveInfo 0 " unknown" 1 "curve entrance" 2 "in a curve" 3 "exit of curve" ;
VAL_ 943 HU_NavCurrentRoadType 0 "Road Type Unknown: Small road, Walking Street" 1 "Road Type Class 1: Secondary Roads" 2 "Road Type Class 2: Mainly Road in City" 3 "Road Type Class 3: Mainly Road in City, Normal Province Road, Mainly street" 4 "Road Type Class 4: Province Road, Mainly Road " 5 "Road Type Class 5: Highway, National Road, Speed road" 6 "Reserved

2.ADAS:
0x0=" 7 "Reserved" ;
VAL_ 943 HU_EnterRampInfo 0 "Unknown" 1 "Ramp entrance" 2 "On the ramp" 3 "ramp exit" ;
VAL_ 943 HU_RampInfo 0 "Unknown" 1 "There is a ramp, but the car does not leave the high speed" 2 "The car enters the high speed through the ramp" 3 "The car exits the highway through the ramp" ;
VAL_ 943 HU_NavStatus 0 "Normal" 1 "Error" ;
VAL_ 943 HU_NavSpeedLimitUnits 3 "reserved" 2 "unit mph" 1 "unit kph" 0 "unknown." ;
VAL_ 943 HU_NavSpeedLimitStatus 3 "reserved" 2 "reserved" 1 "invalid" 0 "valid" ;
VAL_ 943 HU_NavSpeedLimit 31 "SL 155" 30 "SL 150" 29 "SL 145" 28 "SL 140" 27 "SL 135" 26 "SL 130" 25 "SL 125" 24 "SL 120" 23 "SL 115" 22 "SL 110" 21 "SL 105" 20 "SL 100" 19 "SL 95" 18 "SL 90" 17 "SL 85" 16 "SL 80" 15 "SL 75" 14 "SL 70" 13 "SL 65" 12 "SL 60" 11 "SL 55" 10 "SL 50" 9 "SL 45" 8 "SL 40" 7 "SL 35" 6 "SL 30" 5 "SL 25" 4 "SL 20" 3 "SL 15" 0 "Unlimited" 1 "SL 5" 2 "SL 10" 32 "SL 160" 254 "Unknown" 255 "Invalid" ;
VAL_ 952 HU_NavGuiganceStatus 0 "No navigation guide path" 1 "Navigation guide path present" 2 "Reserved" 3 "Reserved" ;
VAL_ 952 HU_SlopeDistance 0 " 0~600m" 61 "Out of Range" 62 "reserved" 63 "unknown" ;
VAL_ 952 HU_Byroad 0 "unknown" 1 "With byroad" 2 "Without byroad" 3 "reserved" ;
VAL_ 952 HU_TunnelLength 0 " 0~600m" 61 "Out of Range" 62 "reserved" 63 "unknown" ;
VAL_ 952 HU_RoadCurvatureFar 0 "0x0~0x1FE: Neg value, Left curve" 8191 "0: No curve, straight line" 512 "0x200~0x3FE: Pos, Right curve" 1023 " unknown" ;
VAL_ 952 HU_TunnelDistance 0 " 0~600m" 61 "Out of Range" 62 "reserved" 63 "unknown" ;
VAL_ 952 HU_RoadCurvature 0 "0x0~0x1FE: Neg value, Left curve" 8191 "0: No curve, straight line" 512 "0x200~0x3FE: Pos, Right curve" 1023 " unknown" ;
VAL_ 952 HU_EnterSlopeInfo 0 "unknown" 1 "Ramp entrance" 2 "in the ramp" 3 "Ramp exit" ;
VAL_ 952 HU_EnterTunnelInfo 0 " unknown" 1 "Tunnel entrance" 2 "In the tunnel" 3 "Tunnel exit" ;
VAL_ 1023 BCM_AutoHeadlightSts 0 "Not Actived" 1 "Actived" ;
VAL_ 1023 BCM_FrontFoglampStatus 0 "OFF" 1 "ON" 2 "Not used" 3 "Reserved" ;
VAL_ 1023 BCM_RearFoglampStatus 0 "OFF" 1 "ON" 2 "Not used" 3 "Error" ;
VAL_ 583 APA_APAOnOff 0 "OFF" 1 "ON" ;
VAL_ 746 ADS_LCDAR_BSD_LCAStatus 0 "OFF()" 1 "Inactive()" 2 "Active" 3 "Failure" ;
VAL_ 746 ADS_LCDAR_Left_BSD_LCAStatus 0 "OFF()" 1 "Inactive()" 2 "Active" 3 "Failure" ;
VAL_ 922 LAS_TSRRightLaneStatus 0 " off" 1 " fusion mode" 2 " vision only mode" 3 " navigation only mode" 4 " reserved" 5 " reserved" 6 " reserved" 7 " Invalid" ;
VAL_ 922 LAS_TSRLeftLaneStatus 0 " off" 1 " fusion mode" 2 " vision only mode" 3 " navigation only mode" 4 " reserved" 5 " reserved" 6 " reserved" 7 " Invalid" ;
VAL_ 922 LAS_TSRRightLaneSpdLimit 255 "SLEND" 254 "Unlimited" 33 "0x21-FD: Reserved" 32 "SL160" 31 "SL155" 30 "SL150" 29 "SL145" 28 "SL140" 27 "SL135" 26 "SL130" 25 "SL125" 24 "SL120" 23 "SL115" 22 "SL110" 21 "SL105" 20 "SL100" 19 "SL95" 18 "SL90" 17 "SL85" 16 "SL80" 15 "SL75" 14 "SL70" 13 "SL65" 12 "SL60" 11 "SL55" 10 "SL50" 9 "SL45" 8 "SL40" 7 "SL35" 6 "SL30" 5 "SL25" 4 "SL20" 3 "SL15" 0 "no display" 1 "SL5" 2 "SL10" ;
VAL_ 922 LAS_TSRLeftLaneSpdLimit 255 "SLEND" 254 "Unlimited" 33 "0x21-FD: Reserved" 32 "SL160" 31 "SL155" 30 "SL150" 29 "SL145" 28 "SL140" 27 "SL135" 26 "SL130" 25 "SL125" 24 "SL120" 23 "SL115" 22 "SL110" 21 "SL105" 20 "SL100" 19 "SL95" 18 "SL90" 17 "SL85" 16 "SL80" 15 "SL75" 14 "SL70" 13 "SL65" 12 "SL60" 11 "SL55" 10 "SL50" 9 "SL45" 8 "SL40" 7 "SL35" 6 "SL30" 5 "SL25" 4 "SL20" 3 "SL15" 0 "no display" 1 "SL5" 2 "SL10" ;
VAL_ 922 LAS_TLAStopLine_HostLane 0 "0-250m" 251 "Reserved" 255 "Out of Range" ;
VAL_ 922 LAS_TLADistance_HostLane 0 "0-250m" 251 "Reserved" 255 "Out of Range" ;
VAL_ 922 LAS_TLACountDownTime_HostLane 0 "no display" 1 "1-120s" 121 "reserved" 127 "out of range" ;
VAL_ 922 LAS_TSRMandatorySign 0 "no display" 1 "Single way (straight)" 2 "Walking" 3 "Main road first" 4 "Oncoming vehicles first" 5 "Crosswalk" 6 "Dedicated lane for bus lines" 7 "reserved" ;
VAL_ 922 LAS_TSRWarningSign 0 "no display" 1 "Reverse detour" 2 "Continuous detour" 3 "Beware of pedestrians" 4 "Beware of children" 5 "Slippery road" 6 "Tunnel" 7 "Slow down" 8 "Construction" 9 "reserved" ;
VAL_ 922 LAS_TSRProhibitionSign 0 "no display" 1 " Prohibit to go through" 2 "No Entry" 3 "Prohibition of motor vehicles" 4 "Prohibit to turn left" 5 "Prohibit to turn right" 6 "Prohibit going straight" 7 "Prohibit to turn around" 8 " Prohibit overtaking" 9 "Cancel Prohibit overtaking" 10 "Prohibit temporary or long-term parking of vehicles" 11 "Prohibit long-term parking of vehicles" 12 "Prohibit honking" 13 "Stop to make way to other vehicles" 14 "Slow down to make way to other vehicles" 15 "Oncoming vehicles first" 16 "0x10~1F: Reserved" ;
VAL_ 922 LAS_OverspeedSoundWarningEnSt 0 "Off" 1 "On" ;
VAL_ 922 LAS_TSREnable 0 "off" 1 "on" ;
VAL_ 922 LAS_HMAEnableStatus 0 "off" 1 "on" ;
VAL_ 922 LAS_HMALightDistribution 0 " High beam not recommended" 1 " High beam recommended" ;
VAL_ 922 LAS_HMAStatus 0 " Off" 1 " Standby" 2 " Active" 3 " Failure" ;
VAL_ 922 LAS_TSRHostSpdLimitUnits 0 "no display" 1 "unit kph" 2 "unit mph" 3 "reserved" ;
VAL_ 922 LAS_TSRHostSpdLimit 255 "SLEND" 254 "Unlimited" 33 "0x21-FD: Reserved" 32 "SL160" 31 "SL155" 30 "SL150" 29 "SL145" 28 "SL140" 27 "SL135" 26 "SL130" 25 "SL125" 24 "SL120" 23 "SL115" 22 "SL110" 21 "SL105" 20 "SL100" 19 "SL95" 18 "SL90" 17 "SL85" 16 "SL80" 15 "SL75" 14 "SL70" 13 "SL65" 12 "SL60" 11 "SL55" 10 "SL50" 9 "SL45" 8 "SL40" 7 "SL35" 6 "SL30" 5 "SL25" 4 "SL20" 3 "SL15" 0 "no display" 1 "SL5" 2 "SL10" ;
VAL_ 922 LAS_TSRStatus 0 " off" 1 " fusion mode" 2 " vision only mode" 3 " navigation only mode" 4 " reserved" 5 " reserved" 6 " reserved" 7 " Invalid" ;
VAL_ 922 LAS_FrontCameraCalibrationStatus 0 " Calibration is ok" 1 " Calibration In Process" 2 " Calibration never done" 3 "  Calibration Failed" ;
VAL_ 922 LAS_FrontCameraFailureStatus 0 "No Error" 1 "camera blocked" 2 "temporary failure" 3 "permanent failure" ;
VAL_ 922 LAS_OverspeedWarningOffset 0 "" 21 "Reserved" 31 "Invalid." ;
VAL_ 922 LAS_OverspeedWarningEnableStatus 0 "OFF" 1 "ON" ;
VAL_ 922 LAS_OverspeedSoundWarning 0 " No Warning" 1 " Warning" ;
VAL_ 922 LAS_OverspeedVisualWarning 0 " No Warning" 1 " Warning" ;
VAL_ 922 LAS_TLAArrowDirection_RightLane 0 "no display" 1 "Forward" 2 "Left" 3 " Forward +Left" 4 "Right" 5 " Forward +Right" 6 "Right+Left" 7 "Left+ Forward +Right" ;
VAL_ 922 LAS_TLAObjectType_RightLane 7 "reserved" 6 "reserved" 0 "no display" 1 "Round" 2 "Arrow" 3 "Turn Round" 4 "X-type" 5 "Arrow+Turn
" ;
VAL_ 922 LAS_TLAObjectStatus_RightLane 0 "no display" 1 "Lighting" 2 "Flashing" 3 " Disappear" ;
VAL_ 922 LAS_TLAObjectColour_RightLane 0 "no display" 1 "Red" 2 "Yellow" 3 "Green" ;
VAL_ 922 LAS_TLAObjectDetection_RightLane 0 "Not Detected" 1 "Detected" ;
VAL_ 922 LAS_TLAArrowDirection_LeftLane 0 "no display" 1 "Forward" 2 "Left" 3 " Forward +Left" 4 "Right" 5 " Forward +Right" 6 "Right+Left" 7 "Left+ Forward +Right" ;
VAL_ 922 LAS_TLAObjectType_LeftLane 7 "reserved" 6 "reserved" 0 "no display" 1 "Round" 2 "Arrow" 3 "Turn Round" 4 "X-type" 5 "Arrow+Turn
" ;
VAL_ 922 LAS_TLAObjectStatus_LeftLane 0 "no display" 1 "Lighting" 2 "Flashing" 3 " Disappear" ;
VAL_ 922 LAS_TLAObjectColour_LeftLane 0 "no display" 1 "Red" 2 "Yellow" 3 "Green" ;
VAL_ 922 LAS_TLAObjectDetection_LeftLane 0 "Not Detected" 1 "Detected" ;
VAL_ 922 LAS_TLAArrowDirection_HostLane 0 "no display" 1 "Forward" 2 "Left" 3 " Forward +Left" 4 "Right" 5 " Forward +Right" 6 "Right+Left" 7 "Left+ Forward +Right" ;
VAL_ 922 LAS_TLAObjectStatus_HostLane 0 "no display" 1 "Lighting" 2 "Flashing" 3 " Disappear" ;
VAL_ 922 LAS_TLAObjectType_HostLane 7 "reserved" 6 "reserved" 0 "no display" 1 "Round" 2 "Arrow" 3 "Turn Round" 4 "X-type" 5 "Arrow+Turn
" ;
VAL_ 922 LAS_TLAObjectColour_HostLane 0 "no display" 1 "Red" 2 "Yellow" 3 "Green" ;
VAL_ 922 LAS_TLAObjectDetection_HostLane 0 "Not Detected" 1 "Detected" ;
VAL_ 922 LAS_TLAWarninglevel 0 " no warning" 1 " warning level 1" 2 " warning level 2" 3 " warning level 3." ;
VAL_ 922 LAS_TLAStatus 0 "OFF" 1 "Standby" 2 "Active" 3 "Failure" ;
VAL_ 922 LAS_TLAEnable 0 "OFF" 1 "ON" ;
VAL_ 999 BCM_Status_Temp 0 "No error" 1 "not used" 2 "HW defect (ADC defect)" 3 "LIN saturation (no HW  defect)" ;
VAL_ 999 BCM_T_BATT 146 "reserved" 255 "Invalid" ;
VAL_ 1000 BCM_SOF_Q_STATE 0 "deviation > 15%" 1 "deviation <15%" 2 "deviation < 10%" 3 "invalid" ;
VAL_ 1000 BCM_SOF_Q 255 "Invalid" ;
